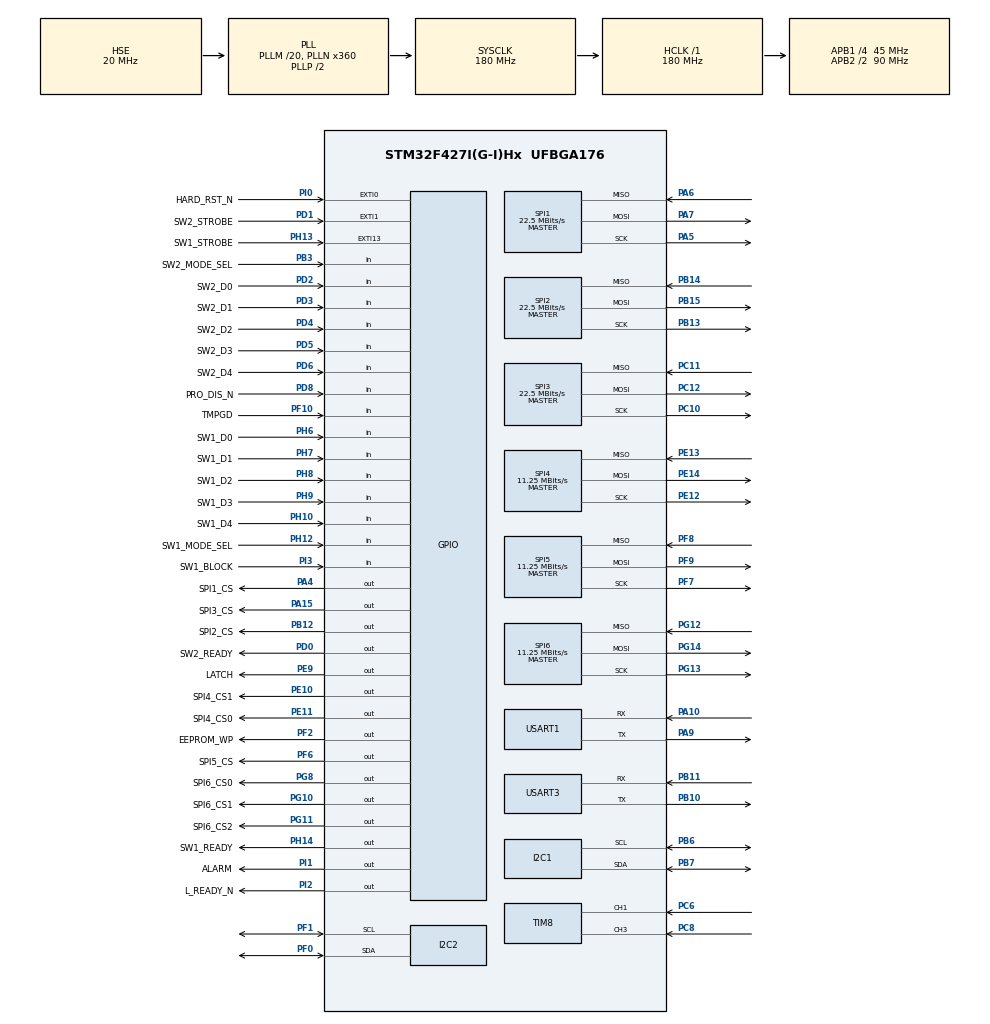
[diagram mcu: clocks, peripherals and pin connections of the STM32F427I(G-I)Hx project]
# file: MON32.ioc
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Dma.Request0=USART1_RX
Dma.USART1_RX.0.Direction=DMA_PERIPH_TO_MEMORY
Dma.USART1_RX.0.FIFOMode=DMA_FIFOMODE_DISABLE
Dma.USART1_RX.0.Instance=DMA2_Stream2
Dma.USART1_RX.0.MemDataAlignment=DMA_MDATAALIGN_BYTE
Dma.USART1_RX.0.MemInc=DMA_MINC_ENABLE
Dma.USART1_RX.0.Mode=DMA_NORMAL
Dma.USART1_RX.0.PeriphDataAlignment=DMA_PDATAALIGN_BYTE
Dma.USART1_RX.0.PeriphInc=DMA_PINC_DISABLE
Dma.USART1_RX.0.Priority=DMA_PRIORITY_VERY_HIGH
FREERTOS.Tasks01=defaultTask,24,128,StartDefaultTask,Default,NULL,Dynamic,NULL,NULL
FREERTOS.configLIBRARY_MAX_SYSCALL_INTERRUPT_PRIORITY=5
IWDG.Prescaler=IWDG_PRESCALER_32
IWDG.Reload=1500
Mcu.Family=STM32F4
Mcu.Name=STM32F427I(G-I)Hx
Mcu.Package=UFBGA176
NVIC.DMA2_Stream2_IRQn=true\:6\:0\:true\:false\:true\:true\:false\:true
NVIC.EXTI0_IRQn=true\:6\:0\:true\:false\:true\:true\:true\:true
NVIC.EXTI15_10_IRQn=true\:6\:0\:true\:false\:true\:true\:true\:true
NVIC.EXTI1_IRQn=true\:6\:0\:true\:false\:true\:true\:true\:true
NVIC.FLASH_IRQn=true\:6\:0\:true\:false\:true\:true\:true\:true
NVIC.PriorityGroup=NVIC_PRIORITYGROUP_4
NVIC.TIM1_TRG_COM_TIM11_IRQn=true\:0\:0\:false\:false\:true\:false\:false\:true
NVIC.TIM6_DAC_IRQn=true\:5\:0\:false\:false\:true\:true\:true\:true
NVIC.TIM8_CC_IRQn=true\:5\:0\:false\:false\:true\:true\:true\:true
NVIC.TimeBase=TIM1_TRG_COM_TIM11_IRQn
NVIC.TimeBaseIP=TIM11
NVIC.USART1_IRQn=true\:6\:0\:true\:false\:true\:true\:true\:true
PA10.Mode=Asynchronous
PA10.Signal=USART1_RX
PA15.GPIO_Label=SPI3_CS
PA15.Signal=GPIO_Output
PA4.GPIO_Label=SPI1_CS
PA4.Signal=GPIO_Output
PA5.Mode=Full_Duplex_Master
PA5.Signal=SPI1_SCK
PA6.Mode=Full_Duplex_Master
PA6.Signal=SPI1_MISO
PA7.Mode=Full_Duplex_Master
PA7.Signal=SPI1_MOSI
PA9.Mode=Asynchronous
PA9.Signal=USART1_TX
PB10.Mode=Asynchronous
PB10.Signal=USART3_TX
PB11.Mode=Asynchronous
PB11.Signal=USART3_RX
PB12.GPIO_Label=SPI2_CS
PB12.Signal=GPIO_Output
PB13.Mode=Full_Duplex_Master
PB13.Signal=SPI2_SCK
PB14.Mode=Full_Duplex_Master
PB14.Signal=SPI2_MISO
PB15.Mode=Full_Duplex_Master
PB15.Signal=SPI2_MOSI
PB3.GPIO_Label=SW2_MODE_SEL
PB3.Signal=GPIO_Input
PB6.Mode=I2C
PB6.Signal=I2C1_SCL
PB7.Mode=I2C
PB7.Signal=I2C1_SDA
PC10.Mode=Full_Duplex_Master
PC10.Signal=SPI3_SCK
PC11.Mode=Full_Duplex_Master
PC11.Signal=SPI3_MISO
PC12.Mode=Full_Duplex_Master
PC12.Signal=SPI3_MOSI
PC14/OSC32_IN.Mode=LSE-External-Oscillator
PC14/OSC32_IN.Signal=RCC_OSC32_IN
PC15/OSC32_OUT.Mode=LSE-External-Oscillator
PC15/OSC32_OUT.Signal=RCC_OSC32_OUT
PC6.Signal=S_TIM8_CH1
PC8.Signal=S_TIM8_CH3
PD0.GPIO_Label=SW2_READY
PD0.GPIO_PuPd=GPIO_PULLUP
PD0.Signal=GPIO_Output
PD1.GPIO_Label=SW2_STROBE
PD1.GPIO_ModeDefaultEXTI=GPIO_MODE_IT_FALLING
PD1.Signal=GPXTI1
PD13.Signal=S_TIM4_CH2
PD14.Signal=S_TIM4_CH3
PD2.GPIO_Label=SW2_D0
PD2.Signal=GPIO_Input
PD3.GPIO_Label=SW2_D1
PD3.Signal=GPIO_Input
PD4.GPIO_Label=SW2_D2
PD4.Signal=GPIO_Input
PD5.GPIO_Label=SW2_D3
PD5.Signal=GPIO_Input
PD6.GPIO_Label=SW2_D4
PD6.Signal=GPIO_Input
PD8.GPIO_Label=PRO_DIS_N
PD8.Signal=GPIO_Input
PE10.GPIO_Label=SPI4_CS1
PE10.Signal=GPIO_Output
PE11.GPIO_Label=SPI4_CS0
PE11.Signal=GPIO_Output
PE12.Mode=Full_Duplex_Master
PE12.Signal=SPI4_SCK
PE13.Mode=Full_Duplex_Master
PE13.Signal=SPI4_MISO
PE14.Mode=Full_Duplex_Master
PE14.Signal=SPI4_MOSI
PE9.GPIO_Label=LATCH
PE9.Signal=GPIO_Output
PF0.Mode=I2C
PF0.Signal=I2C2_SDA
PF1.Mode=I2C
PF1.Signal=I2C2_SCL
PF10.GPIO_Label=TMPGD
PF10.Signal=GPIO_Input
PF2.GPIO_Label=EEPROM_WP
PF2.GPIO_PuPd=GPIO_PULLUP
PF2.Signal=GPIO_Output
PF6.GPIO_Label=SPI5_CS
PF6.Signal=GPIO_Output
PF7.Mode=Full_Duplex_Master
PF7.Signal=SPI5_SCK
PF8.Mode=Full_Duplex_Master
PF8.Signal=SPI5_MISO
PF9.Mode=Full_Duplex_Master
PF9.Signal=SPI5_MOSI
PG10.GPIO_Label=SPI6_CS1
PG10.Signal=GPIO_Output
PG11.GPIO_Label=SPI6_CS2
PG11.Signal=GPIO_Output
PG12.Mode=Full_Duplex_Master
PG12.Signal=SPI6_MISO
PG13.Mode=Full_Duplex_Master
PG13.Signal=SPI6_SCK
PG14.Mode=Full_Duplex_Master
PG14.Signal=SPI6_MOSI
PG8.GPIO_Label=SPI6_CS0
PG8.Signal=GPIO_Output
PH0/OSC_IN.Mode=HSE-External-Oscillator
PH0/OSC_IN.Signal=RCC_OSC_IN
PH1/OSC_OUT.Mode=HSE-External-Oscillator
PH1/OSC_OUT.Signal=RCC_OSC_OUT
PH10.GPIO_Label=SW1_D4
PH10.Signal=GPIO_Input
PH12.GPIO_Label=SW1_MODE_SEL
PH12.Signal=GPIO_Input
PH13.GPIO_Label=SW1_STROBE
PH13.GPIO_ModeDefaultEXTI=GPIO_MODE_IT_FALLING
PH13.Signal=GPXTI13
PH14.GPIO_Label=SW1_READY
PH14.GPIO_PuPd=GPIO_PULLUP
PH14.Signal=GPIO_Output
PH6.GPIO_Label=SW1_D0
PH6.Signal=GPIO_Input
PH7.GPIO_Label=SW1_D1
PH7.Signal=GPIO_Input
PH8.GPIO_Label=SW1_D2
PH8.Signal=GPIO_Input
PH9.GPIO_Label=SW1_D3
PH9.Signal=GPIO_Input
PI0.GPIO_Label=HARD_RST_N
PI0.GPIO_ModeDefaultEXTI=GPIO_MODE_IT_FALLING
PI0.Signal=GPXTI0
PI1.GPIO_Label=ALARM
PI1.GPIO_PuPd=GPIO_PULLUP
PI1.Signal=GPIO_Output
PI2.GPIO_Label=L_READY_N
PI2.GPIO_PuPd=GPIO_PULLUP
PI2.Signal=GPIO_Output
PI3.GPIO_Label=SW1_BLOCK
PI3.Signal=GPIO_Input
ProjectManager.HeapSize=0x200
ProjectManager.StackSize=0x400
ProjectManager.TargetToolchain=MDK-ARM V5
RCC.48MHZClocksFreq_Value=90000000
RCC.AHBFreq_Value=180000000
RCC.APB1CLKDivider=RCC_HCLK_DIV4
RCC.APB1Freq_Value=45000000
RCC.APB1TimFreq_Value=90000000
RCC.APB2CLKDivider=RCC_HCLK_DIV2
RCC.APB2Freq_Value=90000000
RCC.APB2TimFreq_Value=180000000
RCC.CortexFreq_Value=180000000
RCC.HCLKFreq_Value=180000000
RCC.HSE_VALUE=20000000
RCC.HSI_VALUE=16000000
RCC.PLLM=20
RCC.PLLN=360
RCC.PLLSourceVirtual=RCC_PLLSOURCE_HSE
RCC.RCC_RTC_Clock_Source=RCC_RTCCLKSOURCE_LSE
RCC.RCC_RTC_Clock_SourceVirtual=RCC_RTCCLKSOURCE_LSE
RCC.SYSCLKFreq_VALUE=180000000
RCC.SYSCLKSource=RCC_SYSCLKSOURCE_PLLCLK
RCC.VCOOutputFreq_Value=360000000
SH.S_TIM4_CH2.0=TIM4_CH2
SH.S_TIM4_CH3.0=TIM4_CH3
SH.S_TIM8_CH1.0=TIM8_CH1,Input_Capture1_from_TI1
SH.S_TIM8_CH3.0=TIM8_CH3,Input_Capture3_from_TI3
SPI1.BaudRatePrescaler=SPI_BAUDRATEPRESCALER_4
SPI1.CLKPolarity=SPI_POLARITY_HIGH
SPI1.CalculateBaudRate=22.5 MBits/s
SPI1.Direction=SPI_DIRECTION_2LINES
SPI1.Mode=SPI_MODE_MASTER
SPI1.VirtualType=VM_MASTER
SPI2.CLKPhase=SPI_PHASE_1EDGE
SPI2.CLKPolarity=SPI_POLARITY_HIGH
SPI2.CalculateBaudRate=22.5 MBits/s
SPI2.Direction=SPI_DIRECTION_2LINES
SPI2.Mode=SPI_MODE_MASTER
SPI2.VirtualType=VM_MASTER
SPI3.BaudRatePrescaler=SPI_BAUDRATEPRESCALER_2
SPI3.CLKPhase=SPI_PHASE_2EDGE
SPI3.CalculateBaudRate=22.5 MBits/s
SPI3.Direction=SPI_DIRECTION_2LINES
SPI3.Mode=SPI_MODE_MASTER
SPI3.VirtualType=VM_MASTER
SPI4.BaudRatePrescaler=SPI_BAUDRATEPRESCALER_8
SPI4.CalculateBaudRate=11.25 MBits/s
SPI4.Direction=SPI_DIRECTION_2LINES
SPI4.Mode=SPI_MODE_MASTER
SPI4.VirtualType=VM_MASTER
SPI5.BaudRatePrescaler=SPI_BAUDRATEPRESCALER_8
SPI5.CalculateBaudRate=11.25 MBits/s
SPI5.Direction=SPI_DIRECTION_2LINES
SPI5.Mode=SPI_MODE_MASTER
SPI5.VirtualType=VM_MASTER
SPI6.BaudRatePrescaler=SPI_BAUDRATEPRESCALER_8
SPI6.CalculateBaudRate=11.25 MBits/s
SPI6.Direction=SPI_DIRECTION_2LINES
SPI6.Mode=SPI_MODE_MASTER
SPI6.VirtualType=VM_MASTER
TIM6.Period=99
TIM6.Prescaler=89
TIM8.Channel-Input_Capture1_from_TI1=TIM_CHANNEL_1
TIM8.Channel-Input_Capture3_from_TI3=TIM_CHANNEL_3
TIM8.ICFilter_CH1=0x03
TIM8.ICFilter_CH3=0x03
TIM8.ICPolarity_CH3=TIM_INPUTCHANNELPOLARITY_FALLING
USART1.VirtualMode=VM_ASYNC
USART3.VirtualMode=VM_ASYNC
VP_FREERTOS_VS_CMSIS_V2.Mode=CMSIS_V2
VP_IWDG_VS_IWDG.Mode=IWDG_Activate
VP_RTC_VS_RTC_Activate.Mode=RTC_Enabled
VP_SYS_VS_tim11.Mode=TIM11
VP_TIM6_VS_ClockSourceINT.Mode=Enable_Timer
board=custom

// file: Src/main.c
/* USER CODE BEGIN Header */
/**
  ******************************************************************************
  * @file           : main.c
  * @brief          : Main program body
  ******************************************************************************
  * @attention
  *
  * <h2><center>&copy; Copyright (c) 2020 STMicroelectronics.
  * All rights reserved.</center></h2>
  *
  * This software component is licensed by ST under Ultimate Liberty license
  * SLA0044, the "License"; You may not use this file except in compliance with
  * the License. You may obtain a copy of the License at:
  *                             www.st.com/SLA0044
  *
  ******************************************************************************
  */
/* USER CODE END Header */

#include "main.h"
#include "cmsis_os.h"
#include "dma.h"
#include "i2c.h"
#include "iwdg.h"
#include "rtc.h"
#include "spi.h"
#include "tim.h"
#include "usart.h"
#include "gpio.h"

/* USER CODE BEGIN PV */
uint8_t reset_flag = 0;
uint8_t flash_in_use;
UpgradeFlashState upgrade_status;

AlarmHistoryState history_alarm_status;

TosaCalData tosa_table[TOSA_TABLE_COUNT];
uint8_t tosa_table_count = 0;
double tosa_power_high_max_thr = 0;
double tosa_power_low_min_thr = 0;

uint8_t device_busy = 1;
uint8_t allow_tosa = 1; // Indicates allow tosa enable or not. Set by reset.
uint8_t enable_tosa_failed = 0; // Indicates endable tosa failed. Clear when pro_dis_n is 0.

const uint32_t error_file_flash_addr[] =  {  0x08100000, 0x08104000, 0x08108000, 0x0810C000, 0x08110000, 0x08120000,\
                                       0x08140000  };
const uint32_t error_file_flash_end = 0x0815FFFF;
const uint8_t error_file_flash_count = sizeof(error_file_flash_addr) / sizeof (error_file_flash_addr[0]);

const uint32_t normal_file_flash_addr[] =  {  0x08160000, 0x08180000, 0x081A0000};
const uint32_t normal_file_flash_end = 0x081BFFFF;
const uint8_t normal_file_flash_count = sizeof(normal_file_flash_addr) / sizeof (normal_file_flash_addr[0]);

LogFileState log_file_state;

//double power_arr_for_test[10];

RunTimeStatus run_status __attribute__((at(0x2002FC00)));

uint8_t lock_debug = 0;

SwTimControl sw_tim_control;
MsgStruct tim_isr_msg;
MsgStruct pro_isr_msg;
/* USER CODE END PV */

void SystemClock_Config(void);
void MX_FREERTOS_Init(void);

/* USER CODE BEGIN 0 */
extern UpgradeStruct up_state;

/* USER CODE END 0 */

int main(void)
{

  /* MCU Configuration--------------------------------------------------------*/

  /* Reset of all peripherals, Initializes the Flash interface and the Systick. */
  HAL_Init();

  /* Configure the system clock */
  SystemClock_Config();

  /* Initialize all configured peripherals */
  MX_GPIO_Init();
  MX_DMA_Init();
  MX_IWDG_Init();
  MX_RTC_Init();
  MX_I2C1_Init();
  MX_I2C2_Init();
  MX_SPI1_Init();
  MX_SPI2_Init();
  MX_SPI3_Init();
  MX_SPI4_Init();
  MX_SPI5_Init();
  MX_SPI6_Init();
  MX_TIM8_Init();
  MX_USART1_UART_Init();
  MX_USART3_UART_Init();
  MX_TIM6_Init();
  /* USER CODE BEGIN 2 */
  uint8_t buf[3] = {0};
  HAL_GPIO_WritePin(SPI1_CS_GPIO_Port, SPI1_CS_Pin, GPIO_PIN_SET);
  HAL_GPIO_WritePin(SPI2_CS_GPIO_Port, SPI2_CS_Pin, GPIO_PIN_SET);
  HAL_GPIO_WritePin(SPI3_CS_GPIO_Port, SPI3_CS_Pin, GPIO_PIN_RESET);
  if (HAL_SPI_Transmit(&hspi3, buf, 1, 10) != HAL_OK) {
    EPT("spi3 transmit filed when init\n");
  }
  HAL_GPIO_WritePin(SPI4_CS0_GPIO_Port, SPI4_CS0_Pin, GPIO_PIN_SET);
  HAL_GPIO_WritePin(SPI5_CS_GPIO_Port, SPI5_CS_Pin, GPIO_PIN_SET);
  HAL_GPIO_WritePin(SPI6_CS0_GPIO_Port, SPI6_CS0_Pin, GPIO_PIN_SET);

  run_status.internal_exp = 0;
  Set_Flag(&run_status.internal_exp, INT_EXP_CONST);
  /* USER CODE END 2 */
  /* Init scheduler */
  osKernelInitialize();

  /* Call init function for freertos objects (in freertos.c) */
  MX_FREERTOS_Init();

  /* Start scheduler */
  osKernelStart();

  /* We should never get here as control is now taken by the scheduler */

  /* Infinite loop */
  while (1)
  {

  }
}

void SystemClock_Config(void)
{
  RCC_OscInitTypeDef RCC_OscInitStruct = {0};
  RCC_ClkInitTypeDef RCC_ClkInitStruct = {0};
  RCC_PeriphCLKInitTypeDef PeriphClkInitStruct = {0};

  /** Configure the main internal regulator output voltage
  */
  __HAL_RCC_PWR_CLK_ENABLE();
  __HAL_PWR_VOLTAGESCALING_CONFIG(PWR_REGULATOR_VOLTAGE_SCALE1);
  /** Initializes the CPU, AHB and APB busses clocks
  */
  RCC_OscInitStruct.OscillatorType = RCC_OSCILLATORTYPE_LSI|RCC_OSCILLATORTYPE_HSE
                              |RCC_OSCILLATORTYPE_LSE;
  RCC_OscInitStruct.HSEState = RCC_HSE_ON;
  RCC_OscInitStruct.LSEState = RCC_LSE_ON;
  RCC_OscInitStruct.LSIState = RCC_LSI_ON;
  RCC_OscInitStruct.PLL.PLLState = RCC_PLL_ON;
  RCC_OscInitStruct.PLL.PLLSource = RCC_PLLSOURCE_HSE;
  RCC_OscInitStruct.PLL.PLLM = 20;
  RCC_OscInitStruct.PLL.PLLN = 360;
  RCC_OscInitStruct.PLL.PLLP = RCC_PLLP_DIV2;
  RCC_OscInitStruct.PLL.PLLQ = 4;
  if (HAL_RCC_OscConfig(&RCC_OscInitStruct) != HAL_OK)
  {
    Error_Handler();
  }
  /** Activate the Over-Drive mode
  */
  if (HAL_PWREx_EnableOverDrive() != HAL_OK)
  {
    Error_Handler();
  }
  /** Initializes the CPU, AHB and APB busses clocks
  */
  RCC_ClkInitStruct.ClockType = RCC_CLOCKTYPE_HCLK|RCC_CLOCKTYPE_SYSCLK
                              |RCC_CLOCKTYPE_PCLK1|RCC_CLOCKTYPE_PCLK2;
  RCC_ClkInitStruct.SYSCLKSource = RCC_SYSCLKSOURCE_PLLCLK;
  RCC_ClkInitStruct.AHBCLKDivider = RCC_SYSCLK_DIV1;
  RCC_ClkInitStruct.APB1CLKDivider = RCC_HCLK_DIV4;
  RCC_ClkInitStruct.APB2CLKDivider = RCC_HCLK_DIV2;

  if (HAL_RCC_ClockConfig(&RCC_ClkInitStruct, FLASH_LATENCY_5) != HAL_OK)
  {
    Error_Handler();
  }
  PeriphClkInitStruct.PeriphClockSelection = RCC_PERIPHCLK_RTC;
  PeriphClkInitStruct.RTCClockSelection = RCC_RTCCLKSOURCE_LSE;
  if (HAL_RCCEx_PeriphCLKConfig(&PeriphClkInitStruct) != HAL_OK)
  {
    Error_Handler();
  }
}

/* USER CODE BEGIN 4 */
void MON32_Init(void)
{
  osStatus_t status;
  uint32_t i;

  EPT("Firmware version: %s\n", fw_version);

  status = RTOS_EEPROM_Read(EEPROM_ADDR, EE_TAG_PN, (uint8_t*)pn, 16);
  pn[16] = 0;
  status |= RTOS_EEPROM_Read(EEPROM_ADDR, EE_TAG_HW_VERSION, (uint8_t*)hw_version, 4);
  hw_version[4] = 0;
  if (status != osOK) {
    Set_Flag(&run_status.internal_exp, INT_EXP_INIT);
  }

  if (__HAL_RCC_GET_FLAG(RCC_FLAG_BORRST) != RESET){
    SET_RESETFLAG(BOR_RESET_BIT);
    //EPT("BOR Reset is set\n");
  }
  if (__HAL_RCC_GET_FLAG(RCC_FLAG_PINRST) != RESET){
    SET_RESETFLAG(PIN_RESET_BIT);
    //EPT("PIN Reset is set\n");
  }
  if (__HAL_RCC_GET_FLAG(RCC_FLAG_PORRST) != RESET){
    SET_RESETFLAG(POR_RESET_BIT);
    //EPT("POR/PDR Reset is set\n");
  }
  if (__HAL_RCC_GET_FLAG(RCC_FLAG_SFTRST) != RESET){
    SET_RESETFLAG(SFT_RESET_BIT);
    //EPT("Software Reset is set\n");
  }
  if (__HAL_RCC_GET_FLAG(RCC_FLAG_IWDGRST) != RESET){
    SET_RESETFLAG(IWDG_RESET_BIT);
    //EPT("Independent Watchdog Reset is set\n");
  }
  if (__HAL_RCC_GET_FLAG(RCC_FLAG_WWDGRST) != RESET){
    SET_RESETFLAG(WWDG_RESET_BIT);
    //EPT("Window Watchdog Reset is set\n");
  }
  if (__HAL_RCC_GET_FLAG(RCC_FLAG_LPWRRST) != RESET){
    SET_RESETFLAG(LPWR_RESET_BIT);
    //EPT("Low-Power Reset is set\n");
  }
  __HAL_RCC_CLEAR_RESET_FLAGS();
  EPT("Run status maigc = %#X, uart_reset = %u\n", run_status.maigc, run_status.uart_reset);

  status = RTOS_DAC128S085_Write(0, 0, DAC128S085_MODE_WTM);
  if (status != osOK) {
    EPT("Changing DAC128S085 to WTM mode failed\n");
    Set_Flag(&run_status.internal_exp, INT_EXP_OS_ERR);
  }

  update_tosa_table();
  HAL_GPIO_WritePin(SW1_READY_GPIO_Port, SW1_READY_Pin, GPIO_PIN_SET);
  HAL_GPIO_WritePin(SW2_READY_GPIO_Port, SW2_READY_Pin, GPIO_PIN_SET);

  if (IS_RESETFLAG_SET(SFT_RESET_BIT) || IS_RESETFLAG_SET(IWDG_RESET_BIT)) {
    if (run_status.maigc == RUN_MAGIC) {
      if (run_status.uart_reset) {
        run_status.uart_reset = 0;
        EPT("Startup with UART Reset\n");
        THROW_LOG(MSG_TYPE_NORMAL_LOG, "Startup with SOFT Reset\n");
      } else {
        if (IS_RESETFLAG_SET(IWDG_RESET_BIT)) {
          EPT("Startup with WATCHDOG Reset\n");
          THROW_LOG(MSG_TYPE_NORMAL_LOG, "Startup with WATCHDOG Reset\n");
        } else {
          EPT("Startup with HARD Reset\n");
          THROW_LOG(MSG_TYPE_NORMAL_LOG, "Startup with HARD Reset\n");
        }
      }

      // exp signal
      if (run_status.exp) {
        HAL_GPIO_WritePin(ALARM_GPIO_Port, ALARM_Pin, GPIO_PIN_RESET);
      } else {
        HAL_GPIO_WritePin(ALARM_GPIO_Port, ALARM_Pin, GPIO_PIN_SET);
      }
#if 0
      // 2x32 switch signal
      if (run_status.tx_block == 1) {
        HAL_GPIO_WritePin(SW1_READY_GPIO_Port, SW1_READY_Pin, GPIO_PIN_SET);
      } else {
        if (run_status.tx_switch_channel < 0x20) {
          if (run_status.tx_switch_channel == Get_Current_Switch_Channel(TX_SWITCH_CHANNEL)) {
            HAL_GPIO_WritePin(SW1_READY_GPIO_Port, SW1_READY_Pin, GPIO_PIN_RESET);
          } else {
            EPT("Detect 2x32 optical switch channel incorrect while initializing\n");
            THROW_LOG(MSG_TYPE_ERROR_LOG, "Detect 2x32 optical switch channel %u incorrect while initializing\n", run_status.tx_switch_channel);
            Reset_Switch_Only(TX_SWITCH_CHANNEL);
            HAL_GPIO_WritePin(SW1_READY_GPIO_Port, SW1_READY_Pin, GPIO_PIN_SET);
          }
        } else {
          HAL_GPIO_WritePin(SW1_READY_GPIO_Port, SW1_READY_Pin, GPIO_PIN_SET);
        }
      }

      // 1x32 switch signal
      if (run_status.rx_switch_channel < 0x20) {
        if (run_status.rx_switch_channel == Get_Current_Switch_Channel(RX_SWITCH_CHANNEL)) {
          HAL_GPIO_WritePin(SW2_READY_GPIO_Port, SW2_READY_Pin, GPIO_PIN_RESET);
        } else {
          EPT("Detect 1x32 optical switch channel incorrect while initializing\n");
          THROW_LOG(MSG_TYPE_ERROR_LOG, "Detect 1x32 optical switch channel %u incorrect while initializing\n", run_status.rx_switch_channel);
          Reset_Switch_Only(RX_SWITCH_CHANNEL);
          HAL_GPIO_WritePin(SW2_READY_GPIO_Port, SW2_READY_Pin, GPIO_PIN_SET);
        }
      } else {
        HAL_GPIO_WritePin(SW2_READY_GPIO_Port, SW2_READY_Pin, GPIO_PIN_SET);
      }
#endif
      // Modulation
      if (run_status.modulation) {
        HAL_TIM_IC_Start_IT(&htim8, TIM_CHANNEL_1);
        HAL_TIM_IC_Start_IT(&htim8, TIM_CHANNEL_3);
      }

      // Lazer
      if (run_status.lazer_ready) {
        HAL_GPIO_WritePin(L_READY_N_GPIO_Port, L_READY_N_Pin, GPIO_PIN_RESET);
      } else {
        HAL_GPIO_WritePin(L_READY_N_GPIO_Port, L_READY_N_Pin, GPIO_PIN_SET);
      }

      HAL_GPIO_WritePin(LATCH_GPIO_Port, LATCH_Pin, GPIO_PIN_SET);
      osDelay(pdMS_TO_TICKS(1));
      HAL_GPIO_WritePin(LATCH_GPIO_Port, LATCH_Pin, GPIO_PIN_RESET);
    } else {
      // Init device
      Reset_Switch_Only(TX_SWITCH_CHANNEL);
      MON32_Init_Dev();
      EPT("Variable run_status exception\n");
      THROW_LOG(MSG_TYPE_ERROR_LOG, "Variable run_status exception\n");
    }
  } else if (IS_RESETFLAG_SET(BOR_RESET_BIT) || IS_RESETFLAG_SET(POR_RESET_BIT)) {
    // Init device
    MON32_Init_Dev();
    EPT("Startup with POWER Reset\n");
    //THROW_LOG("Startup with POWER Reset\n");
  } else {
    // Init device
    run_status.maigc = 0;
    Reset_Switch_Only(TX_SWITCH_CHANNEL);
    //Disable_Tosa();
    MON32_Init_Dev();
    EPT("Startup with MASTER Reset\n");
    THROW_LOG(MSG_TYPE_NORMAL_LOG, "Startup with MASTER Reset\n");
  }

  up_state.run = RUN_MODE_APPLICATION;
  up_state.is_erasing = 0;
  flash_in_use = 0;

  FLASH_If_Init();
  status = Get_Up_Status(&upgrade_status);
  if (status) {
    EPT("Get upgrade status failed, status = %d\n", status);
    THROW_LOG(MSG_TYPE_ERROR_LOG, "Get upgrade status failed, status = %d\n", status);
  }
  EPT("upgrade_status: %#X, %u, %u, %u, %#X, %u, %#X\n", upgrade_status.magic, upgrade_status.run, upgrade_status.flash_empty, upgrade_status.length, upgrade_status.crc32,\
                upgrade_status.factory_length, upgrade_status.factory_crc32);

  if (upgrade_status.magic != UPGRADE_MAGIC) {
    EPT("Verify upgrade magic failed\n");
    THROW_LOG(MSG_TYPE_ERROR_LOG, "Verify upgrade magic failed\n");
  }
  switch (upgrade_status.run) {
    case 0:
      EPT("Boot from factory\n");
      up_state.upgrade_addr = APPLICATION_1_ADDRESS;
      up_state.upgrade_sector = APPLICATION_1_SECTOR;
      break;
    case 1:
      EPT("Boot from Application 1\n");
      up_state.upgrade_addr = APPLICATION_2_ADDRESS;
      up_state.upgrade_sector = APPLICATION_2_SECTOR;
      break;
    case 2:
      EPT("Boot from Application 2\n");
      up_state.upgrade_addr = APPLICATION_1_ADDRESS;
      up_state.upgrade_sector = APPLICATION_1_SECTOR;
      break;
    default:
      EPT("f_state.run invalid\n");
      THROW_LOG(MSG_TYPE_ERROR_LOG, "f_state.run invalid\n");
      up_state.upgrade_addr = RESERVE_ADDRESS;
      up_state.upgrade_sector = RESERVE_SECTOR;
      break;
  }
  EPT("FLASH->OPTCR = %#X\n", FLASH->OPTCR);
  if (!upgrade_status.flash_empty) {
    flash_in_use = 1;
    up_state.is_erasing = 1;
    // erase flash
    EPT("flash is not empty\n");
    if (up_state.upgrade_addr != RESERVE_ADDRESS)
      FLASH_If_Erase_IT(up_state.upgrade_sector);
    EPT("erase sector...\n");
  } else {
    EPT("flash is empty\n");
  }

  // log
  Get_Log_Status(&log_file_state);
  EPT("log_file_state: %#X, %#X\n", log_file_state.offset, log_file_state.header);
  for (i = 0; i < error_file_flash_count - 1; ++i) {
    if (log_file_state.error_offset < error_file_flash_addr[i + 1]) {
      break;
    }
  }
  log_file_state.error_cur_sector = ERROR_LOG_FIRST_SECTOR + i;

  for (i = 0; i < normal_file_flash_count - 1; ++i) {
    if (log_file_state.normal_offset < normal_file_flash_addr[i + 1]) {
      break;
    }
  }
  log_file_state.normal_cur_sector = NORMAL_LOG_FIRST_SECTOR + i;

  // alarm
  if ((status = Get_EEPROM_Alarm_Status(&history_alarm_status)) != osOK) {
    Set_Flag(&run_status.internal_exp, INT_EXP_OS_ERR);
  }

  // check calibration data
  Check_Cali();
}

void MON32_Init_Dev(void)
{
  osStatus_t status;

  HAL_GPIO_WritePin(ALARM_GPIO_Port, ALARM_Pin, GPIO_PIN_SET);
  HAL_GPIO_WritePin(L_READY_N_GPIO_Port, L_READY_N_Pin, GPIO_PIN_SET);
  HAL_GPIO_WritePin(LATCH_GPIO_Port, LATCH_Pin, GPIO_PIN_SET);
  osDelay(pdMS_TO_TICKS(1));
  HAL_GPIO_WritePin(LATCH_GPIO_Port, LATCH_Pin, GPIO_PIN_RESET);
  Init_Run_Status();
  Get_Threshold_Table(&run_status.thr_table);
  Reset_Tec_Dest_Temp(&run_status.thr_table);

  run_status.tosa_high = Get_Tosa_Data(run_status.tosa_dst_power_high);
  run_status.tosa_low = Get_Tosa_Data(run_status.tosa_dst_power_low);
  status = RTOS_DAC128S085_Write(DAC128S085_TOSA_SWITCH_CHANNEL, 0, DAC128S085_MODE_NORMAL);
  status |= RTOS_DAC128S085_Write(DAC128S085_TEC_SWITCH_CHANNEL, 0, DAC128S085_MODE_NORMAL);
  status |= RTOS_DAC128S085_Write(DAC128S085_TEC_VALUE_CHANNEL, 0, DAC128S085_MODE_NORMAL);
  status |= RTOS_DAC128S085_Write(DAC128S085_TOSA_POWER_CHANNEL, 0, DAC128S085_MODE_NORMAL);
  if (status != osOK) {
    Set_Flag(&run_status.internal_exp, INT_EXP_OS_ERR);
  }
}

extern FLASH_ProcessTypeDef pFlash;
extern osMessageQueueId_t mid_ISR;
extern osMessageQueueId_t mid_SwISR;
extern osMessageQueueId_t mid_LazerManager;
extern osSemaphoreId_t logEraseSemaphore;
void HAL_FLASH_EndOfOperationCallback(uint32_t ReturnValue)
{
  MsgStruct isr_msg;
  if (0xFFFFFFFFU == ReturnValue) {
    EPT("Erase flash operation completely\n");
    HAL_FLASH_Lock();
    flash_in_use = 0;
    if (up_state.is_erasing == 0) {
      // send signal to logTask
      osSemaphoreRelease(logEraseSemaphore);
    } else {
      upgrade_status.flash_empty = 1;
      up_state.is_erasing = 0;
      isr_msg.type = MSG_TYPE_FLASH_ISR;
      osMessageQueuePut(mid_ISR, &isr_msg, 0U, 0U);
    }
  }
}

void HAL_TIM_IC_CaptureCallback(TIM_HandleTypeDef *htim)
{
  if (htim->Instance == TIM8) {
    if (htim->Channel == HAL_TIM_ACTIVE_CHANNEL_1) {
      // Rising Edge
      pro_isr_msg.type = MSG_TYPE_PRO_CTL_RAISING_ISR;
      osMessageQueuePut(mid_LazerManager, &pro_isr_msg, 0U, 0U);
      //RTOS_DAC128S085_Write_Nodelay(DAC128S085_TOSA_POWER_CHANNEL, run_status.tosa_high.tosa_dac, DAC128S085_MODE_NORMAL);
      //run_status.power_mode = 1;
    } else if (htim->Channel == HAL_TIM_ACTIVE_CHANNEL_3) {
      // Failing Edge
      pro_isr_msg.type = MSG_TYPE_PRO_CTL_FALLING_ISR;
      osMessageQueuePut(mid_LazerManager, &pro_isr_msg, 0U, 0U);
      //RTOS_DAC128S085_Write_Nodelay(DAC128S085_TOSA_POWER_CHANNEL, run_status.tosa_low.tosa_dac, DAC128S085_MODE_NORMAL);
      //run_status.power_mode = 0;
    }
  }
}

void HAL_GPIO_EXTI_Callback(uint16_t GPIO_Pin)
{
  MsgStruct isr_msg;

  if (GPIO_Pin == SW1_STROBE_Pin) {
    if (HAL_GPIO_ReadPin(SW1_MODE_SEL_GPIO_Port, SW1_MODE_SEL_Pin) == GPIO_PIN_SET) {
    } else {
      isr_msg.type = MSG_TYPE_SWITCH1_ISR;
      osMessageQueuePut(mid_ISR, &isr_msg, 0U, 0U);
    }
  } else if (GPIO_Pin == SW2_STROBE_Pin) {
    if (HAL_GPIO_ReadPin(SW2_MODE_SEL_GPIO_Port, SW2_MODE_SEL_Pin) == GPIO_PIN_SET) {
    } else {
      isr_msg.type = MSG_TYPE_SWITCH2_ISR;
      osMessageQueuePut(mid_ISR, &isr_msg, 0U, 0U);
    }
  } else if (GPIO_Pin == HARD_RST_N_Pin) {
    __NVIC_SystemReset();
    while (1) {
    }
  }
}

/* USER CODE END 4 */

void HAL_TIM_PeriodElapsedCallback(TIM_HandleTypeDef *htim)
{
  if (htim->Instance == TIM11) {
    HAL_IncTick();
  }
  /* USER CODE BEGIN Callback 1 */
  if (htim->Instance == TIM6) {
    if (++sw_tim_control.counter < sw_tim_control.time) {
    } else {
      HAL_TIM_Base_Stop_IT(&htim6);
      tim_isr_msg.type = MSG_TYPE_SWITCH_DAC_ISR;
      osMessageQueuePut(mid_SwISR, &tim_isr_msg, 0U, 0U);
      sw_tim_control.counter = 0;
    }
  }
  /* USER CODE END Callback 1 */
}

void Error_Handler(void)
{
}

/************************ (C) COPYRIGHT STMicroelectronics *****END OF FILE****/

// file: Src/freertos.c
/* USER CODE BEGIN Header */
/**
  ******************************************************************************
  * File Name          : freertos.c
  * Description        : Code for freertos applications
  ******************************************************************************
  * @attention
  *
  * <h2><center>&copy; Copyright (c) 2020 STMicroelectronics.
  * All rights reserved.</center></h2>
  *
  * This software component is licensed by ST under Ultimate Liberty license
  * SLA0044, the "License"; You may not use this file except in compliance with
  * the License. You may obtain a copy of the License at:
  *                             www.st.com/SLA0044
  *
  ******************************************************************************
  */
/* USER CODE END Header */

#include "FreeRTOS.h"
#include "task.h"
#include "main.h"
#include "cmsis_os.h"

/* USER CODE BEGIN Includes */
#include "command.h"
#include "iwdg.h"
#include "flash_if.h"
#include "functions.h"
#include "tim.h"

/* USER CODE END Includes */

/* USER CODE BEGIN Variables */
osSemaphoreId_t uartProcessSemaphore;
osSemaphoreId_t cmdProcessSemaphore;
osSemaphoreId_t switchSemaphore;
osSemaphoreId_t logEraseSemaphore;                  // semaphore id

osMessageQueueId_t mid_LogMsg;
osMessageQueueId_t mid_ISR;                // message queue id
osMessageQueueId_t mid_SwISR;                // message queue id
osMessageQueueId_t mid_LazerManager;                // message queue id
osMessageQueueId_t mid_CmdProcess;                // message queue id

osMutexId_t i2c1Mutex;
osMutexId_t i2c2Mutex;
osMutexId_t spi2Mutex;
osMutexId_t spi3Mutex;
osMutexId_t spi4Mutex;
osMutexId_t spi5Mutex;
osMutexId_t spi6Mutex;
osMutexId_t swMutex;
const osMutexAttr_t Thread_Mutex_attr = {
  "Mutex",                              // human readable mutex name
  osMutexPrioInherit,                       // attr_bits
  NULL,                                     // memory for control block
  0U                                        // size for control block
};

osThreadId_t cmdProcessTaskHandle;
const osThreadAttr_t cmdProcessTask_attributes = {
  .name = "cmdProcessTask",
  .priority = (osPriority_t) CMD_PROCESS_PRIORITY,
  .stack_size = 2048
};

osThreadId_t uartProcessTaskHandle;
const osThreadAttr_t uartProcessTask_attributes = {
  .name = "uartProcessTask",
  .priority = (osPriority_t) UART_PROCESS_PRIORITY,
  .stack_size = 1024
};

osThreadId_t watchdogTaskHandle;
const osThreadAttr_t watchdogTask_attributes = {
  .name = "watchdogTask",
  .priority = (osPriority_t) WATCHDOG_PRIORITY,
  .stack_size = 512
};

osThreadId_t isrTaskHandle;
const osThreadAttr_t isrTask_attributes = {
  .name = "isrTask",
  .priority = (osPriority_t) INTERRUPT_TASK_PRIORITY,
  .stack_size = 1024
};

osThreadId_t swIsrTaskHandle;
const osThreadAttr_t swIsrTask_attributes = {
  .name = "swIsrTask",
  .priority = (osPriority_t) INTERRUPT_TASK_PRIORITY,
  .stack_size = 1024
};

osThreadId_t logTaskHandle;
const osThreadAttr_t logTask_attributes = {
  .name = "logTask",
  .priority = (osPriority_t) LOG_MESSAGE_PRIORITY,
  .stack_size = 1024
};

osThreadId_t monTaskHandle;
const osThreadAttr_t monTask_attributes = {
  .name = "monTask",
  .priority = (osPriority_t) MONITOR_PRIORITY,
  .stack_size = 1024
};

osThreadId_t lazerManagerTaskHandle;
const osThreadAttr_t lazerManagerTask_attributes = {
  .name = "lazerManagerTask",
  .priority = (osPriority_t) LAZER_MANAGER_PRIORITY,
  .stack_size = 1024
};

/* USER CODE END Variables */
/* Definitions for defaultTask */
osThreadId_t defaultTaskHandle;
const osThreadAttr_t defaultTask_attributes = {
  .name = "defaultTask",
  .priority = (osPriority_t) osPriorityNormal,
  .stack_size = 128
};

/* USER CODE BEGIN FunctionPrototypes */
void uartProcessTask(void *argument);
void cmdProcessTask(void *argument);
void watchdogTask(void *argument);
void isrTask(void *argument);
void swIsrTask(void *argument);
void logTask(void *argument);
void monitorTask(void *argument);
void lazerManagerTask(void *argument);

/* USER CODE END FunctionPrototypes */

void StartDefaultTask(void *argument);

void MX_FREERTOS_Init(void); /* (MISRA C 2004 rule 8.1) */

void MX_FREERTOS_Init(void) {

  /* USER CODE BEGIN RTOS_SEMAPHORES */
  /* add semaphores, ... */
  uartProcessSemaphore = osSemaphoreNew(1U, 0U, NULL);
  if (uartProcessSemaphore == NULL) {
    Set_Flag(&run_status.internal_exp, INT_EXP_INIT);
  }

  cmdProcessSemaphore = osSemaphoreNew(1U, 0U, NULL);
  if (cmdProcessSemaphore == NULL) {
    Set_Flag(&run_status.internal_exp, INT_EXP_INIT);
  }

  switchSemaphore = osSemaphoreNew(1U, 0U, NULL);
  if (switchSemaphore == NULL) {
    Set_Flag(&run_status.internal_exp, INT_EXP_INIT);
  }

  logEraseSemaphore = osSemaphoreNew(1U, 0U, NULL);
  if (logEraseSemaphore == NULL) {
    Set_Flag(&run_status.internal_exp, INT_EXP_INIT);
  }

  mid_LogMsg = osMessageQueueNew(LOG_QUEUE_LENGTH, sizeof(MsgStruct), NULL);
  if (mid_LogMsg == NULL) {
    Set_Flag(&run_status.internal_exp, INT_EXP_INIT);
  }

  mid_ISR = osMessageQueueNew(ISR_QUEUE_LENGTH, sizeof(MsgStruct), NULL);
  if (mid_ISR == NULL) {
    Set_Flag(&run_status.internal_exp, INT_EXP_INIT);
  }

  mid_SwISR = osMessageQueueNew(SW_ISR_QUEUE_LENGTH, sizeof(MsgStruct), NULL);
  if (mid_SwISR == NULL) {
    Set_Flag(&run_status.internal_exp, INT_EXP_INIT);
  }

  mid_LazerManager = osMessageQueueNew(LM_QUEUE_LENGTH, sizeof(MsgStruct), NULL);
  if (mid_LazerManager == NULL) {
    Set_Flag(&run_status.internal_exp, INT_EXP_INIT);
  }

  mid_CmdProcess = osMessageQueueNew(LM_QUEUE_LENGTH, sizeof(MsgStruct), NULL);
  if (mid_CmdProcess == NULL) {
    Set_Flag(&run_status.internal_exp, INT_EXP_INIT);
  }

  i2c1Mutex = osMutexNew(&Thread_Mutex_attr);
  if (i2c1Mutex == NULL) {
    Set_Flag(&run_status.internal_exp, INT_EXP_INIT);
  }

  i2c2Mutex = osMutexNew(&Thread_Mutex_attr);
  if (i2c2Mutex == NULL) {
    Set_Flag(&run_status.internal_exp, INT_EXP_INIT);
  }

  spi2Mutex = osMutexNew(&Thread_Mutex_attr);
  if (spi2Mutex == NULL) {
    Set_Flag(&run_status.internal_exp, INT_EXP_INIT);
  }

  spi3Mutex = osMutexNew(&Thread_Mutex_attr);
  if (spi3Mutex == NULL) {
    Set_Flag(&run_status.internal_exp, INT_EXP_INIT);
  }

  spi4Mutex = osMutexNew(&Thread_Mutex_attr);
  if (spi4Mutex == NULL) {
    Set_Flag(&run_status.internal_exp, INT_EXP_INIT);
  }

  spi5Mutex = osMutexNew(&Thread_Mutex_attr);
  if (spi5Mutex == NULL) {
    Set_Flag(&run_status.internal_exp, INT_EXP_INIT);
  }

  spi6Mutex = osMutexNew(&Thread_Mutex_attr);
  if (spi6Mutex == NULL) {
    Set_Flag(&run_status.internal_exp, INT_EXP_INIT);
  }

  swMutex = osMutexNew(&Thread_Mutex_attr);
  if (swMutex == NULL) {
    Set_Flag(&run_status.internal_exp, INT_EXP_INIT);
  }

  /* USER CODE END RTOS_SEMAPHORES */

  /* Create the thread(s) */
  /* creation of defaultTask */
  defaultTaskHandle = osThreadNew(StartDefaultTask, NULL, &defaultTask_attributes);

  /* USER CODE BEGIN RTOS_THREADS */
  /* add threads, ... */
  uartProcessTaskHandle = osThreadNew(uartProcessTask, NULL, &uartProcessTask_attributes);
  cmdProcessTaskHandle = osThreadNew(cmdProcessTask, NULL, &cmdProcessTask_attributes);
  watchdogTaskHandle = osThreadNew(watchdogTask, NULL, &watchdogTask_attributes);
  isrTaskHandle = osThreadNew(isrTask, NULL, &isrTask_attributes);
  swIsrTaskHandle = osThreadNew(swIsrTask, NULL, &swIsrTask_attributes);
  logTaskHandle = osThreadNew(logTask, NULL, &logTask_attributes);
  monTaskHandle = osThreadNew(monitorTask, NULL, &monTask_attributes);
  lazerManagerTaskHandle = osThreadNew(lazerManagerTask, NULL, &lazerManagerTask_attributes);
  /* USER CODE END RTOS_THREADS */

}

void StartDefaultTask(void *argument)
{
  for(;;)
  {
    osDelay(1);
  }
}

/* USER CODE BEGIN Application */
extern TransStu trans_buf;
extern RespondStu resp_buf;
struct UartTaskSync{
  uint8_t ProcessOnGoing;
  uint8_t ProcessTimeout;
} uart_sync;

void uartProcessTask(void *argument)
{
  uint8_t msg_length;
  uint16_t msg_id;
  uint8_t chk;
  uint32_t wait_time;
  uint16_t *p16;
  osStatus_t status;

  CLEAR_BIT(huart1.Instance->SR, USART_SR_RXNE);
  __HAL_UART_FLUSH_DRREGISTER(&huart1);
  HAL_UART_Receive_IT(&huart1, trans_buf.buf, 1);

  uart_sync.ProcessTimeout = 0;
  uart_sync.ProcessOnGoing = 0;
  trans_buf.stage = TRANS_WAIT_START;

  for(;;)
  {
    if (trans_buf.stage == TRANS_WAIT_START) {
      wait_time = osWaitForever;
    } else if (trans_buf.stage == TRANS_WAIT_HEADER) {
      wait_time = pdMS_TO_TICKS(TRANS_WAIT_HEAD_TIME);
    } else if (trans_buf.stage == TRANS_RECV_DATA) {
      wait_time = pdMS_TO_TICKS(TRANS_WAIT_TIME);
    }
    status = osSemaphoreAcquire(uartProcessSemaphore, wait_time / 2);
    if (status != osOK) {
      HAL_UART_DMAStop(&huart1);
      EPT("DMA timeout, stage = %u, ErrorCode = %#X\n", trans_buf.stage, huart1.ErrorCode);
      THROW_LOG(MSG_TYPE_ERROR_LOG, "DMA timeout, stage = %u, ErrorCode = %#X\n", trans_buf.stage, huart1.ErrorCode);
      Uart_Respond(msg_id, RESPOND_FAILURE, NULL, 0);
      trans_buf.stage = TRANS_WAIT_START;
      HAL_UART_Receive_IT(&huart1, trans_buf.buf, 1);
      continue;
    }

    if (trans_buf.stage == TRANS_WAIT_START) {
      // Received start byte
      if (trans_buf.buf[0] != TRANS_START_BYTE) {
        // Invalid data
        EPT("Invalid character: %#X\n", trans_buf.buf[0]);
        HAL_UART_Receive_IT(&huart1, trans_buf.buf, 1);
      } else {
        // Prepare to receive message header
        msg_id = 0;
        trans_buf.stage = TRANS_WAIT_HEADER;
        HAL_UART_Receive_DMA(&huart1, &trans_buf.buf[1], 3);
      }
    } else if (trans_buf.stage == TRANS_WAIT_HEADER) {
      // Received message header
      p16 = (uint16_t*)&trans_buf.buf[CMD_SEQ_MSG_ID];
      msg_id = switch_endian_16(*p16);
      msg_length = trans_buf.buf[CMD_SEQ_MSG_LENGTH];
      if (msg_length < 4) {
        // Length invalid
        PRINT_HEX("buf", trans_buf.buf, 4);
        EPT("Invalid length %#X\n", msg_length);
        THROW_LOG(MSG_TYPE_ERROR_LOG, "Invalid length %#X\n", msg_length);
        Uart_Respond(msg_id, RESPOND_FAILURE, NULL, 0);
        trans_buf.stage = TRANS_WAIT_START;
        HAL_UART_Receive_IT(&huart1, trans_buf.buf, 1);
      } else {
        trans_buf.stage = TRANS_RECV_DATA;
        HAL_UART_Receive_DMA(&huart1, &trans_buf.buf[CMD_SEQ_MSG_DATA], msg_length - 3);
        //EPT("Message Length: %u, ID: %u\n", msg_length, msg_id);
        trans_buf.length = msg_length + 1;
      }
    } else if (trans_buf.stage == TRANS_RECV_DATA){
      // Received message data
      //PRINT_HEX("buf", trans_buf.buf, trans_buf.length);

      // TODO: Check CRC
      chk = Cal_Check((uint8_t*)&trans_buf.buf[1], trans_buf.length - 1 - 1);
      if (chk ^ trans_buf.buf[trans_buf.length - 1]) {
        // Incorrect
        THROW_LOG(MSG_TYPE_ERROR_LOG, "UART Checksum verification failed, msg_length = %#X, cid = %#X, chk = %#X, rcv_chk = %#X\n",\
          msg_length, msg_id, chk, trans_buf.buf[trans_buf.length - 1]);
        EPT("msg_length = %#X, trans_buf.length = %#X, chk = %#X, rcv_chk = %#X\n", msg_length, trans_buf.length, chk, trans_buf.buf[trans_buf.length - 1]);
        PRINT_HEX("buf", trans_buf.buf, trans_buf.length);
        FILL_RESP_MSG(msg_id, RESPOND_CHECK_ERR, 0);
      } else {
        if (!uart_sync.ProcessOnGoing) {
          // Process Command and Respond
          xTaskNotifyGive(cmdProcessTaskHandle);
          status = osSemaphoreAcquire(cmdProcessSemaphore, pdMS_TO_TICKS(COMMAND_PROCESS_TIME) / 2);
          if (status == osErrorTimeout) {
            // TODO: Process command timeout
            THROW_LOG(MSG_TYPE_ERROR_LOG, "Process command %#X timeout\n", msg_id);
            EPT("Process command timeout\n");
            uart_sync.ProcessTimeout = 1;
            FILL_RESP_MSG(msg_id, RESPOND_FAILURE, 0);
          } else if (status != osOK) {
            EPT("Error, status=%#X\n", status);
            THROW_LOG(MSG_TYPE_ERROR_LOG, "Process command failed, status=%#X\n", status);
            FILL_RESP_MSG(msg_id, RESPOND_FAILURE, 0);
          } else {
            // success
          }
        } else {
            EPT("Detected process is ongoing\n");
            THROW_LOG(MSG_TYPE_ERROR_LOG, "Detected process is ongoing\n");
            FILL_RESP_MSG(msg_id, RESPOND_FAILURE, 0);
        }
      }

      trans_buf.stage = TRANS_WAIT_START;
      HAL_UART_Receive_IT(&huart1, trans_buf.buf, 1);
      Uart_Respond(resp_buf.cmd, resp_buf.status, resp_buf.buf, resp_buf.length);
    }
  }
}

void cmdProcessTask(void *argument)
{
  for (;;)
  {
    ulTaskNotifyTake(pdTRUE, portMAX_DELAY);
    if (trans_buf.stage != TRANS_RECV_DATA) {
      EPT("Stage incorrect\n");
      THROW_LOG(MSG_TYPE_ERROR_LOG, "Stage incorrect\n");
      continue;
    }

    uart_sync.ProcessOnGoing = 1;
    Cmd_Process();

    if (uart_sync.ProcessTimeout == 0) {
      osSemaphoreRelease(cmdProcessSemaphore);
      //Uart_Respond(resp_buf.cmd, resp_buf.status, resp_buf.buf, resp_buf.length);
    } else {
      EPT("Detected process timeout\n");
      THROW_LOG(MSG_TYPE_ERROR_LOG, "Detected process timeout\n");
      uart_sync.ProcessTimeout = 0;
    }

    uart_sync.ProcessOnGoing = 0;
  }
}

void watchdogTask(void *argument)
{
  uint32_t delay = pdMS_TO_TICKS(WATCH_DOG_DELAY_TIME);

  HAL_IWDG_Refresh(&hiwdg);
  for(;;)
  {
    //EPT("Feed dog\n");
    osDelay(delay);
    HAL_IWDG_Refresh(&hiwdg);
  }
}

extern UpgradeFlashState upgrade_status;
void isrTask(void *argument)
{
  osStatus_t status;
  MsgStruct msg;
  uint8_t switch_channel, switch_pos;
  //uint32_t switch_channel;

  MON32_Init();

  for (;;)
  {
    status = osMessageQueueGet(mid_ISR, &msg, 0U, osWaitForever);
    if (status != osOK)
      continue;

    if (msg.type == MSG_TYPE_FLASH_ISR) {
      EPT("Received MSG_TYPE_FLASH_ISR, flash_empty = %u\n", upgrade_status.flash_empty);
      status = Update_Up_Status(&upgrade_status);
      if (status != osOK) {
        EPT("Update upgrade status to eeprom failed\n");
      }
    } else if (msg.type == MSG_TYPE_SWITCH1_ISR) {
      switch_channel = TX_SWITCH_CHANNEL;
      switch_pos = Get_Switch_Position_By_IO(switch_channel);
      EPT("Switch channel is %u, Switch position is %u\n", switch_channel, switch_pos);
      if (switch_pos >= 0x20) {
        EPT("Invalid switch position = %u [io]\n", switch_pos);
        THROW_LOG(MSG_TYPE_ERROR_LOG, "Invalid switch position = %u [io]\n", switch_pos);
        continue;
      }

      if (run_status.tx_block) {
        run_status.tx_switch_channel = switch_pos;
        continue;
      }

      if ((status = osMutexAcquire(swMutex, 50)) != osOK) {
        THROW_LOG(MSG_TYPE_ERROR_LOG, "Acquire mutex of sw failed\n");
        continue;
      }

      Clear_Switch_Ready(switch_channel);
      if (Set_Switch(switch_channel, switch_pos)) {
        run_status.tx_switch_channel = 0xFF;
        THROW_LOG(MSG_TYPE_NORMAL_LOG, "Set Switch failed in io mode\n");
        osMutexRelease(swMutex);
        continue;
      }

      run_status.tx_switch_channel = switch_pos;

      // Check
      if (Get_Current_Switch_Channel(switch_channel) != switch_pos) {
        Reset_Switch(switch_channel);
        THROW_LOG(MSG_TYPE_NORMAL_LOG, "Check Switch abnormal\n");
        osMutexRelease(swMutex);
        continue;
      }

      Set_Switch_Ready(switch_channel);
      osMutexRelease(swMutex);
    } else if (msg.type == MSG_TYPE_SWITCH2_ISR) {
      switch_channel = RX_SWITCH_CHANNEL;
      switch_pos = Get_Switch_Position_By_IO(switch_channel);
      EPT("Switch channel is %u, Switch position is %u\n", switch_channel, switch_pos);
      if (switch_pos >= 0x20) {
        EPT("Invalid switch position = %u [io]\n", switch_pos);
        THROW_LOG(MSG_TYPE_ERROR_LOG, "Invalid switch position = %u [io]\n", switch_pos);
        continue;
      }

      if ((status = osMutexAcquire(swMutex, 50)) != osOK) {
        THROW_LOG(MSG_TYPE_ERROR_LOG, "Acquire mutex of sw failed\n");
        continue;
      }

      Clear_Switch_Ready(switch_channel);
      if (Set_Switch(switch_channel, switch_pos)) {
        run_status.rx_switch_channel = 0xFF;
        THROW_LOG(MSG_TYPE_NORMAL_LOG, "Set Switch failed in io mode\n");
        osMutexRelease(swMutex);
        continue;
      }

      run_status.rx_switch_channel = switch_pos;
      // osDelay(pdMS_TO_TICKS(4));

      // Check
      if (Get_Current_Switch_Channel(switch_channel) != switch_pos) {
        Reset_Switch(switch_channel);
        THROW_LOG(MSG_TYPE_NORMAL_LOG, "Check Switch abnormal\n");
        osMutexRelease(swMutex);
        continue;
      }

      Set_Switch_Ready(switch_channel);
      osMutexRelease(swMutex);
    } else if (msg.type == MSG_TYPE_SELF_CHECK_SWITCH) {
      if (run_status.osc_status == OSC_ONGOING) {
        msg.type = MSG_TYPE_SELF_TEST_STEP_2;
        msg.pbuf = NULL;

        if ((status = osMutexAcquire(swMutex, 50)) != osOK) {
          THROW_LOG(MSG_TYPE_ERROR_LOG, "Acquire mutex of sw failed\n");
          run_status.osc_status = OSC_FAILURE;
          osMessageQueuePut(mid_LazerManager, &msg, 0U, 0U);
          continue;
        }

        // Switch Loopback
        Clear_Switch_Ready(TX_SWITCH_CHANNEL);
        if (Set_Switch(TX_SWITCH_CHANNEL, 32)) {
          run_status.tx_switch_channel = 0xFF;
          THROW_LOG(MSG_TYPE_ERROR_LOG, "Set Tx Switch failed\n");
          run_status.osc_status = OSC_FAILURE;
          osMutexRelease(swMutex);
          osMessageQueuePut(mid_LazerManager, &msg, 0U, 0U);
          continue;
        }
        run_status.tx_switch_channel = 32;
        // Check
        if (Get_Current_Switch_Channel(TX_SWITCH_CHANNEL) != 32) {
          THROW_LOG(MSG_TYPE_ERROR_LOG, "Set Tx Switch failed 2\n");
          run_status.osc_status = OSC_FAILURE;
          osMutexRelease(swMutex);
          osMessageQueuePut(mid_LazerManager, &msg, 0U, 0U);
          continue;
        }

        Clear_Switch_Ready(RX_SWITCH_CHANNEL);
        if (Set_Switch(RX_SWITCH_CHANNEL, 32)) {
          run_status.rx_switch_channel = 0xFF;
          THROW_LOG(MSG_TYPE_ERROR_LOG, "Set Rx Switch failed\n");
          run_status.osc_status = OSC_FAILURE;
          osMutexRelease(swMutex);
          osMessageQueuePut(mid_LazerManager, &msg, 0U, 0U);
          continue;
        }
        run_status.rx_switch_channel = 32;
        // Check
        if (Get_Current_Switch_Channel(RX_SWITCH_CHANNEL) != 32) {
          THROW_LOG(MSG_TYPE_ERROR_LOG, "Set Rx Switch failed 2\n");
          run_status.osc_status = OSC_FAILURE;
          osMutexRelease(swMutex);
          osMessageQueuePut(mid_LazerManager, &msg, 0U, 0U);
          continue;
        }

        osMutexRelease(swMutex);
        osMessageQueuePut(mid_LazerManager, &msg, 0U, 0U);
      } else if (run_status.osc_status == OSC_SUCCESS) {
        if ((status = osMutexAcquire(swMutex, 50)) != osOK) {
          THROW_LOG(MSG_TYPE_ERROR_LOG, "Acquire mutex of sw failed\n");
          continue;
        }

        Clear_Switch_Ready(TX_SWITCH_CHANNEL);
        if (run_status.tx_block) {
          Reset_Switch_Only(TX_SWITCH_CHANNEL);
          run_status.tx_switch_channel = 0;
        } else {
          if (Set_Switch(TX_SWITCH_CHANNEL, 0)) {
            run_status.tx_switch_channel = 0xFF;
            THROW_LOG(MSG_TYPE_ERROR_LOG, "Set Tx Switch failed\n");
            osMutexRelease(swMutex);
            continue;
          }
          run_status.tx_switch_channel = 0;
          // Check
          if (Get_Current_Switch_Channel(TX_SWITCH_CHANNEL) != 0) {
            THROW_LOG(MSG_TYPE_ERROR_LOG, "Set Tx Switch failed 2\n");
            osMutexRelease(swMutex);
            continue;
          }
          Set_Switch_Ready(TX_SWITCH_CHANNEL);
        }

        Clear_Switch_Ready(RX_SWITCH_CHANNEL);
        if (Set_Switch(RX_SWITCH_CHANNEL, 0)) {
          run_status.rx_switch_channel = 0xFF;
          THROW_LOG(MSG_TYPE_ERROR_LOG, "Set Rx Switch failed\n");
          osMutexRelease(swMutex);
          continue;
        }
        run_status.rx_switch_channel = 0;
        // Check
        if (Get_Current_Switch_Channel(RX_SWITCH_CHANNEL) != 0) {
          THROW_LOG(MSG_TYPE_ERROR_LOG, "Set Rx Switch failed 2\n");
          osMutexRelease(swMutex);
          continue;
        }
        Set_Switch_Ready(RX_SWITCH_CHANNEL);
        osMutexRelease(swMutex);
      } else if (run_status.osc_status == OSC_FAILURE) {
        if ((status = osMutexAcquire(swMutex, 50)) != osOK) {
          THROW_LOG(MSG_TYPE_ERROR_LOG, "Acquire mutex of sw failed\n");
          continue;
        }

        Reset_Switch(TX_SWITCH_CHANNEL);

        Clear_Switch_Ready(RX_SWITCH_CHANNEL);
        if (Set_Switch(RX_SWITCH_CHANNEL, 0)) {
          run_status.rx_switch_channel = 0xFF;
          THROW_LOG(MSG_TYPE_ERROR_LOG, "Set Rx Switch failed\n");
          osMutexRelease(swMutex);
          continue;
        }
        run_status.rx_switch_channel = 0;
        // Check
        if (Get_Current_Switch_Channel(RX_SWITCH_CHANNEL) != 0) {
          THROW_LOG(MSG_TYPE_ERROR_LOG, "Set Rx Switch failed 2\n");
          osMutexRelease(swMutex);
          continue;
        }
        Set_Switch_Ready(RX_SWITCH_CHANNEL);
        osMutexRelease(swMutex);
      }
    }
  }
}

void swIsrTask(void *argument)
{
  osStatus_t status;
  MsgStruct msg;

  for (;;)
  {
    status = osMessageQueueGet(mid_SwISR, &msg, 0U, osWaitForever);
    if (status != osOK)
      continue;

    if (msg.type == MSG_TYPE_SWITCH_DAC_ISR) {
      if (sw_tim_control.cur_x < sw_tim_control.dst_x) {
        sw_tim_control.cur_x = (sw_tim_control.dst_x - sw_tim_control.cur_x > sw_tim_control.step) ?\
                                (sw_tim_control.cur_x + sw_tim_control.step) : (sw_tim_control.dst_x);
      } else if (sw_tim_control.cur_x > sw_tim_control.dst_x) {
        sw_tim_control.cur_x = (sw_tim_control.cur_x - sw_tim_control.dst_x > sw_tim_control.step) ?\
                                (sw_tim_control.cur_x - sw_tim_control.step) : (sw_tim_control.dst_x);
      }

      if (sw_tim_control.cur_y < sw_tim_control.dst_y) {
        sw_tim_control.cur_y = (sw_tim_control.dst_y - sw_tim_control.cur_y > sw_tim_control.step) ?\
                                (sw_tim_control.cur_y + sw_tim_control.step) : (sw_tim_control.dst_y);
      } else if (sw_tim_control.cur_y > sw_tim_control.dst_y) {
        sw_tim_control.cur_y = (sw_tim_control.cur_y - sw_tim_control.dst_y > sw_tim_control.step) ?\
                                (sw_tim_control.cur_y - sw_tim_control.step) : (sw_tim_control.dst_y);
      }

      set_sw_dac_2(sw_tim_control.sw_num, sw_tim_control.cur_x, sw_tim_control.cur_y);

      if (sw_tim_control.cur_x == sw_tim_control.dst_x && sw_tim_control.cur_y == sw_tim_control.dst_y) {
        osSemaphoreRelease(switchSemaphore);
      } else {
        HAL_TIM_Base_Start_IT(&htim6);
      }
    }
  }
}

void logTask(void *argument)
{
  MsgStruct log_msg;
  osStatus_t status;
  uint32_t write_length;
  uint8_t remainder;

  uint32_t error_overflow_addr;
  uint32_t error_next_sector_addr;
  uint8_t error_next_sector;

  uint32_t normal_overflow_addr;
  uint32_t normal_next_sector_addr;
  uint8_t normal_next_sector;

  osDelay(pdMS_TO_TICKS(500));

  if (log_file_state.error_cur_sector == ERROR_LOG_FIRST_SECTOR + error_file_flash_count - 1) {
    error_overflow_addr = error_file_flash_end + 1;
    error_next_sector_addr = error_file_flash_addr[0];
    error_next_sector = ERROR_LOG_FIRST_SECTOR;
  } else {
    error_next_sector_addr = error_overflow_addr = error_file_flash_addr[log_file_state.error_cur_sector - ERROR_LOG_FIRST_SECTOR + 1];
    error_next_sector = log_file_state.error_cur_sector + 1;
  }

  if (log_file_state.normal_cur_sector == NORMAL_LOG_FIRST_SECTOR + normal_file_flash_count - 1) {
    normal_overflow_addr = normal_file_flash_end + 1;
    normal_next_sector_addr = normal_file_flash_addr[0];
    normal_next_sector = NORMAL_LOG_FIRST_SECTOR;
  } else {
    normal_next_sector_addr = normal_overflow_addr = normal_file_flash_addr[log_file_state.normal_cur_sector - NORMAL_LOG_FIRST_SECTOR + 1];
    normal_next_sector = log_file_state.normal_cur_sector + 1;
  }

  for (;;)
  {
    status = osMessageQueueGet(mid_LogMsg, &log_msg, 0U, osWaitForever);
    if (status != osOK)
      continue;

    if (log_msg.type == MSG_TYPE_ERROR_LOG) {
      if (log_file_state.error_offset >= error_file_flash_end + 1 || log_file_state.error_offset < error_file_flash_addr[0]) {
        Set_Flag(&run_status.internal_exp, INT_EXP_LOG_TASK);
        continue;
      }

      // The final amount of data written to flash must be an integer multiple of 4
      remainder = log_msg.length % 4;
      if (remainder) remainder = 4 - remainder;
      if (log_file_state.error_offset + log_msg.length + remainder >= error_overflow_addr) {
        // 1. fill the rest space with ' '
        Log_Write_byte(log_file_state.error_offset, ' ', error_overflow_addr - log_file_state.error_offset - 4);
        Log_Write_byte(log_file_state.error_offset + error_overflow_addr - log_file_state.error_offset - 4, '\n', 4);

        // 2. erase flash
        while (flash_in_use) {
          osDelay(pdMS_TO_TICKS(200));
        }
        //THROW_LOG("Log space overflow, erasing flash sector %u\n", next_sector);
        osSemaphoreAcquire(logEraseSemaphore, 0);
        if (FLASH_If_Erase_IT(error_next_sector) == FLASHIF_OK) {
          flash_in_use = 1;
        } else {
          Set_Flag(&run_status.internal_exp, INT_EXP_LOG_ERASE);
        }

        // 3. waiting for completion
        osSemaphoreAcquire(logEraseSemaphore, osWaitForever);

        // 4. update log_file_state, overflow_addr and next_***s
        log_file_state.error_offset = error_next_sector_addr;
        log_file_state.error_cur_sector = error_next_sector;
        if (log_file_state.error_cur_sector == ERROR_LOG_FIRST_SECTOR + error_file_flash_count - 1) {
          error_overflow_addr = error_file_flash_end + 1;
          error_next_sector_addr = error_file_flash_addr[0];
          error_next_sector = ERROR_LOG_FIRST_SECTOR;
        } else {
          error_next_sector_addr = error_overflow_addr = error_file_flash_addr[log_file_state.error_cur_sector - ERROR_LOG_FIRST_SECTOR + 1];
          error_next_sector = log_file_state.error_cur_sector + 1;
        }
        if (log_file_state.error_offset == log_file_state.error_header) {
          log_file_state.error_header = error_next_sector_addr;
        }
      }

      EPT("Writing log to flash address %#X, header = %#X\n", log_file_state.offset, log_file_state.header);
      while (flash_in_use) {
        EPT("Flash in using...\n");
        osDelay(pdMS_TO_TICKS(200));
      }
      write_length = Log_Write(log_file_state.error_offset, log_msg.pbuf, log_msg.length);
      log_file_state.error_offset += write_length;
    } else if (log_msg.type == MSG_TYPE_NORMAL_LOG) {
      if (log_file_state.normal_offset >= normal_file_flash_end + 1 || log_file_state.normal_offset < normal_file_flash_addr[0]) {
        Set_Flag(&run_status.internal_exp, INT_EXP_LOG_TASK);
        continue;
      }

      // The final amount of data written to flash must be an integer multiple of 4
      remainder = log_msg.length % 4;
      if (remainder) remainder = 4 - remainder;
      if (log_file_state.normal_offset + log_msg.length + remainder >= normal_overflow_addr) {
        // 1. fill the rest space with ' '
        Log_Write_byte(log_file_state.normal_offset, ' ', normal_overflow_addr - log_file_state.normal_offset - 4);
        Log_Write_byte(log_file_state.normal_offset + normal_overflow_addr - log_file_state.normal_offset - 4, '\n', 4);

        // 2. erase flash
        while (flash_in_use) {
          osDelay(pdMS_TO_TICKS(200));
        }
        //THROW_LOG("Log space overflow, erasing flash sector %u\n", next_sector);
        osSemaphoreAcquire(logEraseSemaphore, 0);
        if (FLASH_If_Erase_IT(normal_next_sector) == FLASHIF_OK) {
          flash_in_use = 1;
        } else {
          Set_Flag(&run_status.internal_exp, INT_EXP_LOG_ERASE);
        }

        // 3. waiting for completion
        osSemaphoreAcquire(logEraseSemaphore, osWaitForever);

        // 4. update log_file_state, overflow_addr and next_***s
        log_file_state.normal_offset = normal_next_sector_addr;
        log_file_state.normal_cur_sector = normal_next_sector;
        if (log_file_state.normal_cur_sector == NORMAL_LOG_FIRST_SECTOR + normal_file_flash_count - 1) {
          normal_overflow_addr = normal_file_flash_end + 1;
          normal_next_sector_addr = normal_file_flash_addr[0];
          normal_next_sector = NORMAL_LOG_FIRST_SECTOR;
        } else {
          normal_next_sector_addr = normal_overflow_addr = normal_file_flash_addr[log_file_state.normal_cur_sector - NORMAL_LOG_FIRST_SECTOR + 1];
          normal_next_sector = log_file_state.normal_cur_sector + 1;
        }
        if (log_file_state.normal_offset == log_file_state.normal_header) {
          log_file_state.normal_header = normal_next_sector_addr;
        }
      }

      EPT("Writing log to flash address %#X, header = %#X\n", log_file_state.offset, log_file_state.header);
      while (flash_in_use) {
        EPT("Flash in using...\n");
        osDelay(pdMS_TO_TICKS(200));
      }
      write_length = Log_Write(log_file_state.normal_offset, log_msg.pbuf, log_msg.length);
      log_file_state.normal_offset += write_length;
    } else {
      Set_Flag(&run_status.internal_exp, INT_EXP_LOG_TASK);
      continue;
    }

    vPortFree(log_msg.pbuf);

    if (osMessageQueueGetCount(mid_LogMsg) == 0) {
      // update log_file_state to eeprom/flash
      Update_Log_Status(&log_file_state);
    }
  }
}

void monitorTask(void *argument)
{
  osStatus_t status;
  uint16_t value;
  uint8_t ret;
  double voltage, temp;
  MsgStruct msg;

  osDelay(pdMS_TO_TICKS(500));

  if (!(IS_RESETFLAG_SET(SFT_RESET_BIT) || IS_RESETFLAG_SET(IWDG_RESET_BIT))) {
    if (Set_Switch(RX_SWITCH_CHANNEL, 0)) {
      run_status.rx_switch_channel = 0xFF;
    }
    run_status.rx_switch_channel = 0;
    // Check
    if (Get_Current_Switch_Channel(RX_SWITCH_CHANNEL) != 0) {
      Reset_Switch(RX_SWITCH_CHANNEL);
    } else {
      Set_Switch_Ready(RX_SWITCH_CHANNEL);
    }
  }

  device_busy = 0;

  for (;;) {
    // 2x32 Switch Block signal
    if (HAL_GPIO_ReadPin(SW1_BLOCK_GPIO_Port, SW1_BLOCK_Pin) == GPIO_PIN_RESET) {
      if (!run_status.tx_block) {
        Clear_Switch_Ready(TX_SWITCH_CHANNEL);
        Reset_Switch_Only(TX_SWITCH_CHANNEL);
        run_status.tx_block = 1;
      }
    } else {
      if (run_status.tx_block) {
        if (run_status.tx_switch_channel != 0xFF) {
          if (Set_Switch(TX_SWITCH_CHANNEL, run_status.tx_switch_channel)) {
            THROW_LOG(MSG_TYPE_ERROR_LOG, "Set Tx Switch failed\n");
            run_status.tx_switch_channel = 0xFF;
            continue;
          }

          // Check
          if (Get_Current_Switch_Channel(TX_SWITCH_CHANNEL) != run_status.tx_switch_channel) {
            THROW_LOG(MSG_TYPE_NORMAL_LOG, "Check Switch abnormal\n");
            Reset_Switch(TX_SWITCH_CHANNEL);
            continue;
          } else {
            Set_Switch_Ready(TX_SWITCH_CHANNEL);
          }
        }
        run_status.tx_block = 0;
      }
    }

    // PRO_Dis signal
    if (HAL_GPIO_ReadPin(PRO_DIS_N_GPIO_Port, PRO_DIS_N_Pin) == GPIO_PIN_RESET) {
      if (!run_status.tosa_enable && allow_tosa && !enable_tosa_failed) {
        run_status.tosa_enable = 1;
        msg.type = MSG_TYPE_LAZER_ENABLE;
        osMessageQueuePut(mid_LazerManager, &msg, 0U, 0U);
      }
    } else {
      enable_tosa_failed = 0;
      if (run_status.tosa_enable) {
        run_status.tosa_enable = 0;
        msg.type = MSG_TYPE_LAZER_DISABLE;
        osMessageQueuePut(mid_LazerManager, &msg, 0U, 0U);
      }
    }

    // Alarm
    status = RTOS_ADC7828_Read(VOLTAGE_3_3_CHANNEL, &value);
    if (status != osOK) {
      Set_Flag(&run_status.internal_exp, INT_EXP_OS_ERR);
    } else {
      voltage = (double)value / 4096 * 2.5 * 2;
      if (!Is_Flag_Set(&run_status.exp, EXP_VOLTAGE_3_3)) {
        if (voltage > run_status.thr_table.vol_3_3_high_alarm || voltage < run_status.thr_table.vol_3_3_low_alarm) {
          THROW_LOG(MSG_TYPE_NORMAL_LOG, "Voltage 3.3V abnormal, current voltage = %.3lfV\n", voltage);
          Set_Flag(&run_status.exp, EXP_VOLTAGE_3_3);
        }
      } else {
        if (voltage <= run_status.thr_table.vol_3_3_high_clear && voltage >= run_status.thr_table.vol_3_3_low_clear) {
          THROW_LOG(MSG_TYPE_NORMAL_LOG, "Voltage 3.3V back to normal\n");
          Clear_Flag(&run_status.exp, EXP_VOLTAGE_3_3);
        }
      }
    }

    status = RTOS_ADC7953_SPI5_Read(TEC_ADC_VOLTAGE_4_4_CHANNEL, &value);
    if (status != osOK) {
      Set_Flag(&run_status.internal_exp, INT_EXP_OS_ERR);
    } else {
      voltage = (double)value / 4096 * 2.5 * 3;
      if (!Is_Flag_Set(&run_status.exp, EXP_VOLTAGE_4_4)) {
        if (voltage > run_status.thr_table.vol_4_4_high_alarm || voltage < run_status.thr_table.vol_4_4_low_alarm) {
          THROW_LOG(MSG_TYPE_NORMAL_LOG, "Voltage 4.4V abnormal, current voltage = %.3lfV\n", voltage);
          Set_Flag(&run_status.exp, EXP_VOLTAGE_4_4);
        }
      } else {
        if (voltage <= run_status.thr_table.vol_4_4_high_clear && voltage >= run_status.thr_table.vol_4_4_low_clear) {
          THROW_LOG(MSG_TYPE_NORMAL_LOG, "Voltage 4.4V back to normal\n");
          Clear_Flag(&run_status.exp, EXP_VOLTAGE_4_4);
        }
      }
    }

    status = RTOS_ADC7828_Read(VOLTAGE_5_0_CHANNEL, &value);
    if (status != osOK) {
      Set_Flag(&run_status.internal_exp, INT_EXP_OS_ERR);
      value = 0;
    } else {
      voltage = (double)value / 4096 * 2.5 * 3;
      if (!Is_Flag_Set(&run_status.exp, EXP_VOLTAGE_5_0)) {
        if (voltage > run_status.thr_table.vol_5_0_high_alarm || voltage < run_status.thr_table.vol_5_0_low_alarm) {
          THROW_LOG(MSG_TYPE_NORMAL_LOG, "Voltage 5V abnormal, current voltage = %.3lfV\n", voltage);
          Set_Flag(&run_status.exp, EXP_VOLTAGE_5_0);
        }
      } else {
        if (voltage <= run_status.thr_table.vol_5_0_high_clear && voltage >= run_status.thr_table.vol_5_0_low_clear) {
          THROW_LOG(MSG_TYPE_NORMAL_LOG, "Voltage 5V back to normal\n");
          Clear_Flag(&run_status.exp, EXP_VOLTAGE_5_0);
        }
      }
    }

    status = RTOS_ADC7828_Read(VOLTAGE_61_0_CHANNEL, &value);
    if (status != osOK) {
      Set_Flag(&run_status.internal_exp, INT_EXP_OS_ERR);
      value = 0;
    } else {
      voltage = (double)value / 4096 * 2.5 * 51;
      if (!Is_Flag_Set(&run_status.exp, EXP_VOLTAGE_61_0)) {
        if (voltage > run_status.thr_table.vol_61_0_high_alarm || voltage < run_status.thr_table.vol_61_0_low_alarm) {
          THROW_LOG(MSG_TYPE_NORMAL_LOG, "Voltage 64V abnormal, current voltage = %.3lfV\n", voltage);
          Set_Flag(&run_status.exp, EXP_VOLTAGE_61_0);
        }
      } else {
        if (voltage <= run_status.thr_table.vol_61_0_high_clear && voltage >= run_status.thr_table.vol_61_0_low_clear) {
          THROW_LOG(MSG_TYPE_NORMAL_LOG, "Voltage 64V back to normal\n");
          Clear_Flag(&run_status.exp, EXP_VOLTAGE_61_0);
        }
      }
    }

    status = RTOS_ADC7828_Read(TEMPERATURE_CHANNEL, &value);
    if (status != osOK) {
      Set_Flag(&run_status.internal_exp, INT_EXP_OS_ERR);
      value = 0;
    } else {
      temp = Cal_Temp(value);
      if (!Is_Flag_Set(&run_status.exp, EXP_TEMPERATURE)) {
        if (temp > run_status.thr_table.temp_high_alarm || temp < run_status.thr_table.temp_low_alarm) {
          THROW_LOG(MSG_TYPE_NORMAL_LOG, "Temperature abnormal, current temperature = %.3lfC\n", temp);
          Set_Flag(&run_status.exp, EXP_TEMPERATURE);
        }
      } else {
        if (temp <= run_status.thr_table.temp_high_clear && temp >= run_status.thr_table.temp_low_clear) {
          THROW_LOG(MSG_TYPE_NORMAL_LOG, "Temperature back to normal\n");
          Clear_Flag(&run_status.exp, EXP_TEMPERATURE);
        }
      }
    }

#if 1
    if (run_status.allow_monitor) {
      if (run_status.tosa_enable) {
        status = RTOS_ADC7953_SPI5_Read(TEC_ADC_TEC_CURRENT_CHANNEL, &value);
        if (status != osOK) {
          Set_Flag(&run_status.internal_exp, INT_EXP_OS_ERR);
        } else {
          voltage = (double)value / 4096 * 2.5;
          voltage = (voltage - 1.25) / 0.285 * 1000;
          if (!Is_Flag_Set(&run_status.exp, EXP_TEC_CURRENT)) {
            if (voltage > run_status.thr_table.tec_cur_high_alarm || voltage < run_status.thr_table.tec_cur_low_alarm) {
              THROW_LOG(MSG_TYPE_NORMAL_LOG, "Tec current abnormal, current current = %.lfmA\n", voltage);
              Set_Flag(&run_status.exp, EXP_TEC_CURRENT);
            }
          } else {
            if (voltage <= run_status.thr_table.tec_cur_high_clear && voltage >= run_status.thr_table.tec_cur_low_clear) {
              THROW_LOG(MSG_TYPE_NORMAL_LOG, "Tec current back to normal\n");
              Clear_Flag(&run_status.exp, EXP_TEC_CURRENT);
            }
          }
        }

        status = RTOS_ADC7953_SPI5_Read(TEC_ADC_TEC_VOLTAGE_CHANNEL, &value);
        if (status != osOK) {
          Set_Flag(&run_status.internal_exp, INT_EXP_OS_ERR);
        } else {
          voltage = (double)value / 4096 * 2.5;
          voltage = (voltage - 1.25) / 0.25 * 1000;
          if (!Is_Flag_Set(&run_status.exp, EXP_TEC_VOLTAGE)) {
            if (voltage > run_status.thr_table.tec_vol_high_alarm || voltage < run_status.thr_table.tec_vol_low_alarm) {
              THROW_LOG(MSG_TYPE_NORMAL_LOG, "Tec voltage abnormal, current voltage = %.lfmV\n", voltage);
              Set_Flag(&run_status.exp, EXP_TEC_VOLTAGE);
            }
          } else {
            if (voltage <= run_status.thr_table.tec_vol_high_clear && voltage >= run_status.thr_table.tec_vol_low_clear) {
              THROW_LOG(MSG_TYPE_NORMAL_LOG, "Tec voltage back to normal\n");
              Clear_Flag(&run_status.exp, EXP_TEC_VOLTAGE);
            }
          }
        }
      }
  #endif

      if (run_status.tosa_enable) {
        // Power
        if (!run_status.modulation) {
          if ((ret = get_tap_pd_power(&value, &voltage)) != 0) {
            if (!Is_Flag_Set(&run_status.internal_exp, INT_EXP_TAP_PD)) {
              THROW_LOG(MSG_TYPE_ERROR_LOG, "Get_Tap_Power error code = %u\n", ret);
              Set_Flag(&run_status.internal_exp, INT_EXP_TAP_PD);
            }
          } else {
            temp = run_status.tosa_dst_power_high - voltage;
            if (temp > 2 || temp < -2) {
              if (!Is_Flag_Set(&run_status.exp, EXP_LAZER_POWER)) {
                THROW_LOG(MSG_TYPE_NORMAL_LOG, "Tap power = %lf, destination is %lf\n", voltage, run_status.tosa_dst_power_high);
                Set_Flag(&run_status.exp, EXP_LAZER_POWER);
              }
            } else {
              if (Is_Flag_Set(&run_status.exp, EXP_LAZER_POWER)) {
                THROW_LOG(MSG_TYPE_NORMAL_LOG, "Tap power = %lf back to normal\n", voltage);
                Clear_Flag(&run_status.exp, EXP_LAZER_POWER);
              }
            }
          }
        }

        // TEC LOSS LOCK
        if (HAL_GPIO_ReadPin(TMPGD_GPIO_Port, TMPGD_Pin) == GPIO_PIN_RESET) {
          if (!Is_Flag_Set(&run_status.exp, EXP_TEC_TEMP_LOSS)) {
            THROW_LOG(MSG_TYPE_NORMAL_LOG, "TEC lock loss\n");
            Set_Flag(&run_status.exp, EXP_TEC_TEMP_LOSS);
          }
        } else {
          if (Is_Flag_Set(&run_status.exp, EXP_TEC_TEMP_LOSS)) {
            THROW_LOG(MSG_TYPE_NORMAL_LOG, "TEC locked\n");
            Clear_Flag(&run_status.exp, EXP_TEC_TEMP_LOSS);
          }
        }

        // Tec Temperature
        status = RTOS_ADC7953_SPI5_Read(TEC_ADC_TEC_TEMP_CHANNEL, &value);
        if (status != osOK) {
          Set_Flag(&run_status.internal_exp, INT_EXP_OS_ERR);
          value = 0;
        } else {
          temp = Cal_Tosa_Temp(value);
          if (!Is_Flag_Set(&run_status.exp, EXP_TEC_TEMP)) {
            if (temp > run_status.thr_table.tec_temp_high_alarm || temp < run_status.thr_table.tec_temp_low_alarm) {
              THROW_LOG(MSG_TYPE_NORMAL_LOG, "Tec Temperature abnormal, current temperature = %.3lfC\n", temp);
              Set_Flag(&run_status.exp, EXP_TEC_TEMP);
            }
          } else {
            if (temp <= run_status.thr_table.tec_temp_high_clear && temp >= run_status.thr_table.tec_temp_low_clear) {
              THROW_LOG(MSG_TYPE_NORMAL_LOG, "Tec Temperature back to normal\n");
              Clear_Flag(&run_status.exp, EXP_TEC_TEMP);
            }
          }
        }

        // LD Current
        status = RTOS_ADC7953_SPI5_Read(TEC_ADC_LD_CURRENT_CHANNEL, &value);
        if (status != osOK) {
          Set_Flag(&run_status.internal_exp, INT_EXP_OS_ERR);
          value = 0;
        } else {
          temp = (double)value / 4096 * 2.5;
          temp = temp / 22 * 1000;
          if (!Is_Flag_Set(&run_status.exp, EXP_LAZER_CURRENT)) {
            if (temp > run_status.thr_table.LD_cur_high_alarm) {
              THROW_LOG(MSG_TYPE_NORMAL_LOG, "LD Current abnormal, current temperature = %.3lfC\n", temp);
              Set_Flag(&run_status.exp, EXP_LAZER_CURRENT);
            }
          } else {
            if (temp <= run_status.thr_table.LD_cur_high_clear) {
              THROW_LOG(MSG_TYPE_NORMAL_LOG, "LD Current back to normal\n");
              Clear_Flag(&run_status.exp, EXP_LAZER_CURRENT);
            }
          }
        }
      }
    }

    if (run_status.exp && !run_status.pre_alarm) {
      Set_Alarm();
      if (Update_History_Alarm(run_status.exp) != osOK) {
        Set_Flag(&run_status.internal_exp, INT_EXP_UP_ALARM);
      }
      run_status.pre_alarm = 1;
      run_status.pre_exp_value = run_status.exp;
    } else if (!run_status.exp && run_status.pre_alarm) {
      Clear_Alarm();
      run_status.pre_alarm = 0;
      run_status.pre_exp_value = 0;
    } else if (run_status.exp && run_status.pre_alarm) {
      if (run_status.exp != run_status.pre_exp_value) {
        if (Update_History_Alarm(run_status.exp) != osOK) {
          Set_Flag(&run_status.internal_exp, INT_EXP_UP_ALARM);
        }
        run_status.pre_exp_value = run_status.exp;
      }
    }

    if (run_status.modulation) {
      osDelay(pdMS_TO_TICKS(1000));
    } else {
      osDelay(pdMS_TO_TICKS(300));
    }
  }
}

void lazerManagerTask(void *argument)
{
  osStatus_t status;
  uint8_t buf[2];
  uint8_t ret;
  MsgStruct msg;
  double power_cur, power_sub, power_dst;
  uint32_t i, times;

  osDelay(pdMS_TO_TICKS(500));

  for (;;)
  {
    status = osMessageQueueGet(mid_LazerManager, &msg, 0U, osWaitForever);
    if (status != osOK)
      continue;

    if (msg.type == MSG_TYPE_LAZER_ENABLE) {
      run_status.tosa_high = Get_Tosa_Data(run_status.tosa_dst_power_high);
      run_status.tosa_low = Get_Tosa_Data(run_status.tosa_dst_power_low);

      if (run_status.modulation) {
        status = RTOS_DAC128S085_Write(DAC128S085_TEC_VALUE_CHANNEL, (run_status.tosa_high.tec_dac + run_status.tosa_low.tec_dac) / 2, DAC128S085_MODE_NORMAL);
        if (run_status.power_mode) {
          RTOS_DAC128S085_Write(DAC128S085_TOSA_POWER_CHANNEL, run_status.tosa_high.tosa_dac, DAC128S085_MODE_NORMAL);
        } else {
          RTOS_DAC128S085_Write(DAC128S085_TOSA_POWER_CHANNEL, run_status.tosa_low.tosa_dac, DAC128S085_MODE_NORMAL);
        }
      } else {
        status = RTOS_DAC128S085_Write(DAC128S085_TEC_VALUE_CHANNEL, run_status.tosa_high.tec_dac, DAC128S085_MODE_NORMAL);
        RTOS_DAC128S085_Write(DAC128S085_TOSA_POWER_CHANNEL, run_status.tosa_high.tosa_dac, DAC128S085_MODE_NORMAL);
      }

      if ((ret = Enable_Tosa()) != 0) {
        Set_Flag(&run_status.internal_exp, INT_EXP_TOSA);
        THROW_LOG(MSG_TYPE_ERROR_LOG, "Enable Tosa failed, ret = %u\n", ret);
        enable_tosa_failed = 1;
        continue;
      }
      osDelay(pdMS_TO_TICKS(100));

      if (!run_status.modulation) {
        if (Cali_Power(run_status.tosa_dst_power_high)) {
          allow_tosa = 0;
          run_status.tosa_enable = 0;
          THROW_LOG(MSG_TYPE_NORMAL_LOG, "Module has disabled Tosa until reset\n");
          Disable_Tosa();
          continue;
        }
      }

      Set_Lazer_Ready();

      i = 0;
      times = 0;
      while (i++ < 100) {
        if (Is_Tec_Lock()) {
          if (++times > 5) {
            break;
          }
        }
        osDelay(5);
      }
      if (times > 5) {
        Update_Tec_Dest_Temp(&run_status.thr_table);
      } else {
        THROW_LOG(MSG_TYPE_ERROR_LOG, "TMPGD error\n");
        Set_Flag(&run_status.exp, EXP_TEC_TEMP_LOSS);
        break;
      }
      run_status.allow_monitor = 1;
    } else if (msg.type == MSG_TYPE_LAZER_DISABLE) {
      run_status.allow_monitor = 0;
      Clear_Lazer_Ready();

      Disable_Tosa();
    } else if (msg.type == MSG_TYPE_LAZER_POWER) {
      //msg.type = MSG_TYPE_CMD_PROCESS;
      //msg.pbuf = pvPortMalloc(1);
      //msg.length = 1;

      run_status.tosa_high = Get_Tosa_Data(run_status.tosa_dst_power_high);
      run_status.tosa_low = Get_Tosa_Data(run_status.tosa_dst_power_low);

      if (run_status.tosa_enable) {
        run_status.allow_monitor = 0;

        if (run_status.modulation) {
          status = RTOS_DAC128S085_Write(DAC128S085_TEC_VALUE_CHANNEL, (run_status.tosa_high.tec_dac + run_status.tosa_low.tec_dac) / 2, DAC128S085_MODE_NORMAL);
          if (run_status.power_mode) {
            RTOS_DAC128S085_Write(DAC128S085_TOSA_POWER_CHANNEL, run_status.tosa_high.tosa_dac, DAC128S085_MODE_NORMAL);
          } else {
            RTOS_DAC128S085_Write(DAC128S085_TOSA_POWER_CHANNEL, run_status.tosa_low.tosa_dac, DAC128S085_MODE_NORMAL);
          }
        } else {
          status = RTOS_DAC128S085_Write(DAC128S085_TEC_VALUE_CHANNEL, run_status.tosa_high.tec_dac, DAC128S085_MODE_NORMAL);
          RTOS_DAC128S085_Write(DAC128S085_TOSA_POWER_CHANNEL, run_status.tosa_high.tosa_dac, DAC128S085_MODE_NORMAL);
          osDelay(1);
          if (Cali_Power(run_status.tosa_dst_power_high)) {
            THROW_LOG(MSG_TYPE_NORMAL_LOG, "Module has disabled Tosa until reset\n");
            allow_tosa = 0;
            run_status.tosa_enable = 0;
            Disable_Tosa();
            // return failure
            //*(uint8_t*)msg.pbuf = 1;
            //osMessageQueuePut(mid_CmdProcess, &msg, 0U, 0U);
            continue;
          }
        }

        // return success
        //*(uint8_t*)msg.pbuf = 0;
        //osMessageQueuePut(mid_CmdProcess, &msg, 0U, 0U);

        i = 0;
        times = 0;
        while (i++ < 100) {
          if (Is_Tec_Lock()) {
            if (++times > 5) {
              break;
            }
          }
          osDelay(5);
        }
        if (times > 5) {
          Update_Tec_Dest_Temp(&run_status.thr_table);
        } else {
          THROW_LOG(MSG_TYPE_ERROR_LOG, "TMPGD error\n");
          Set_Flag(&run_status.exp, EXP_TEC_TEMP_LOSS);
          break;
        }
        run_status.allow_monitor = 1;
      } else {
        // return success
        //*(uint8_t*)msg.pbuf = 0;
        //osMessageQueuePut(mid_CmdProcess, &msg, 0U, 0U);
      }
    } else if (msg.type == MSG_TYPE_MODULATION_ON) {
      //msg.type = MSG_TYPE_CMD_PROCESS;
      //msg.pbuf = pvPortMalloc(1);
      //msg.length = 1;

      if (run_status.tosa_enable) {
        run_status.allow_monitor = 0;

        status = RTOS_DAC128S085_Write(DAC128S085_TEC_VALUE_CHANNEL, (run_status.tosa_high.tec_dac + run_status.tosa_low.tec_dac) / 2, DAC128S085_MODE_NORMAL);

        run_status.modulation = 1;
        HAL_TIM_IC_Start_IT(&htim8, TIM_CHANNEL_1);
        HAL_TIM_IC_Start_IT(&htim8, TIM_CHANNEL_3);

        i = 0;
        times = 0;
        while (i++ < 100) {
          if (Is_Tec_Lock()) {
            if (++times > 5) {
              break;
            }
          }
          osDelay(5);
        }
        if (times > 5) {
          Update_Tec_Dest_Temp(&run_status.thr_table);
        } else {
          THROW_LOG(MSG_TYPE_ERROR_LOG, "TMPGD error\n");
          Set_Flag(&run_status.exp, EXP_TEC_TEMP_LOSS);
          break;
        }
        run_status.allow_monitor = 1;
      } else {
        run_status.modulation = 1;
        HAL_TIM_IC_Start_IT(&htim8, TIM_CHANNEL_1);
        HAL_TIM_IC_Start_IT(&htim8, TIM_CHANNEL_3);
      }

      //*(uint8_t*)msg.pbuf = 0;
      //osMessageQueuePut(mid_CmdProcess, &msg, 0U, 0U);

    } else if (msg.type == MSG_TYPE_MODULATION_OFF) {
      //msg.type = MSG_TYPE_CMD_PROCESS;
      //msg.pbuf = pvPortMalloc(1);
      //msg.length = 1;

      HAL_TIM_IC_Stop_IT(&htim8, TIM_CHANNEL_1);
      HAL_TIM_IC_Stop_IT(&htim8, TIM_CHANNEL_3);

      run_status.power_mode = 1;

      if (run_status.tosa_enable) {
        run_status.allow_monitor = 0;

        status = RTOS_DAC128S085_Write(DAC128S085_TEC_VALUE_CHANNEL, run_status.tosa_high.tec_dac, DAC128S085_MODE_NORMAL);
        RTOS_DAC128S085_Write(DAC128S085_TOSA_POWER_CHANNEL, run_status.tosa_high.tosa_dac, DAC128S085_MODE_NORMAL);
        osDelay(pdMS_TO_TICKS(1));

        if (Cali_Power(run_status.tosa_dst_power_high)) {
          THROW_LOG(MSG_TYPE_NORMAL_LOG, "Module has disabled Tosa until reset\n");
          allow_tosa = 0;
          run_status.tosa_enable = 0;
          Disable_Tosa();
          // return failure
          //*(uint8_t*)msg.pbuf = 1;
          //osMessageQueuePut(mid_CmdProcess, &msg, 0U, 0U);
          continue;
        }

        i = 0;
        times = 0;
        while (i++ < 100) {
          if (Is_Tec_Lock()) {
            if (++times > 5) {
              break;
            }
          }
          osDelay(5);
        }
        if (times > 5) {
          Update_Tec_Dest_Temp(&run_status.thr_table);
        } else {
          THROW_LOG(MSG_TYPE_ERROR_LOG, "TMPGD error\n");
          Set_Flag(&run_status.exp, EXP_TEC_TEMP_LOSS);
          break;
        }
        run_status.allow_monitor = 1;
      }

      run_status.modulation = 0;
      //*(uint8_t*)msg.pbuf = 0;
      //osMessageQueuePut(mid_CmdProcess, &msg, 0U, 0U);
    } else if (msg.type == MSG_TYPE_SELF_TEST) {
      if (Is_Flag_Set(&run_status.exp, EXP_SELFCHECK)) {
        Clear_Flag(&run_status.exp, EXP_SELFCHECK);
      }
      if (Is_Flag_Set(&run_status.exp, EXP_RX_PD)) {
        Clear_Flag(&run_status.exp, EXP_RX_PD);
      }
      if (Is_Flag_Set(&run_status.exp, EXP_SWITCH)) {
        Clear_Flag(&run_status.exp, EXP_SWITCH);
      }

      run_status.osc_status = OSC_ONGOING;
      msg.type = MSG_TYPE_SELF_CHECK_SWITCH;
      msg.pbuf = NULL;
      osMessageQueuePut(mid_ISR, &msg, 0U, 0U);
    } else if (msg.type == MSG_TYPE_SELF_TEST_STEP_2) {
      msg.type = MSG_TYPE_SELF_CHECK_SWITCH;
      msg.pbuf = NULL;
      if (run_status.osc_status == OSC_FAILURE) {
        if (!Is_Flag_Set(&run_status.exp, EXP_SELFCHECK)) {
          Set_Flag(&run_status.exp, EXP_SELFCHECK);
        }
        osMessageQueuePut(mid_ISR, &msg, 0U, 0U);
        continue;
      }

      if ((ret = Get_Tap_Power(&power_cur)) != 0) {
        THROW_LOG(MSG_TYPE_NORMAL_LOG, "Self-check failed because get tap-pd failed.\n");
        THROW_LOG(MSG_TYPE_ERROR_LOG, "Get_Tap_Power error code = %u when self_check\n", ret);
        Set_Flag(&run_status.internal_exp, INT_EXP_TAP_PD);
        if (!Is_Flag_Set(&run_status.exp, EXP_SELFCHECK)) {
          Set_Flag(&run_status.exp, EXP_SELFCHECK);
        }
        run_status.osc_status = OSC_FAILURE;
        osMessageQueuePut(mid_ISR, &msg, 0U, 0U);
        continue;
      }
      power_sub = run_status.tosa_dst_power_high - power_cur;
      // THROW_LOG(MSG_TYPE_NORMAL_LOG, "Self-check Tap power = %lf, dest power is %lf\r\n", power_h, run_status.tosa_dst_power_high);
      if (power_sub > 2 || power_sub < -2) {
        THROW_LOG(MSG_TYPE_NORMAL_LOG, "Self-check failed.\n");
        THROW_LOG(MSG_TYPE_NORMAL_LOG, "Tap power = %lf, destination is %lf\n", power_cur, run_status.tosa_dst_power_high);
        if (!Is_Flag_Set(&run_status.exp, EXP_SELFCHECK)) {
          Set_Flag(&run_status.exp, EXP_SELFCHECK);
        }
        if (!Is_Flag_Set(&run_status.exp, EXP_LAZER_POWER)) {
          Set_Flag(&run_status.exp, EXP_LAZER_POWER);
        }
        run_status.osc_status = OSC_FAILURE;
        osMessageQueuePut(mid_ISR, &msg, 0U, 0U);
        continue;
      }

      if ((ret = Get_Rx_Power(&power_cur)) != 0) {
        THROW_LOG(MSG_TYPE_NORMAL_LOG, "Self-check failed because get rx-pd failed.\n");
        THROW_LOG(MSG_TYPE_ERROR_LOG, "Get_Rx_Power error code = %u when self_check\n", ret);
        Set_Flag(&run_status.internal_exp, INT_EXP_RX_PD);
        if (!Is_Flag_Set(&run_status.exp, EXP_SELFCHECK)) {
          Set_Flag(&run_status.exp, EXP_SELFCHECK);
        }
        run_status.osc_status = OSC_FAILURE;
        osMessageQueuePut(mid_ISR, &msg, 0U, 0U);
        continue;
      }
      status = RTOS_EEPROM_Read(EEPROM_ADDR, EE_CAL_LB_IL + 2, buf, 2);
      // power_dst is loopback insertion loss vale
      power_dst = (double)(int16_t)Buffer_To_BE16(buf) / 100;
      power_sub = run_status.tosa_dst_power_high - (power_cur + power_dst);
      // THROW_LOG(MSG_TYPE_NORMAL_LOG, "Self-check Rx power = %lf, IL = %lf, dest power is %lf, \r\n", power_h, power_dst, run_status.tosa_dst_power_high);
      if (power_sub > 3 || power_sub < -3) {
        THROW_LOG(MSG_TYPE_NORMAL_LOG, "Self-check failed.\n");
        THROW_LOG(MSG_TYPE_NORMAL_LOG, "Rx power = %lf, IL = %lf, destination is %lf\n", power_cur, power_dst, run_status.tosa_dst_power_high);
        if (power_sub > 60 || power_sub < -60) {
          if (!Is_Flag_Set(&run_status.exp, EXP_SWITCH)) {
            Set_Flag(&run_status.exp, EXP_SWITCH);
          }
        } else {
          if (!Is_Flag_Set(&run_status.exp, EXP_RX_PD)) {
            Set_Flag(&run_status.exp, EXP_RX_PD);
          }
        }
        if (!Is_Flag_Set(&run_status.exp, EXP_SELFCHECK)) {
          Set_Flag(&run_status.exp, EXP_SELFCHECK);
        }
        run_status.osc_status = OSC_FAILURE;
        osMessageQueuePut(mid_ISR, &msg, 0U, 0U);
        continue;
      }

      if (Is_Flag_Set(&run_status.exp, EXP_SELFCHECK)) {
        Clear_Flag(&run_status.exp, EXP_SELFCHECK);
      }
      run_status.osc_status = OSC_SUCCESS;
      osMessageQueuePut(mid_ISR, &msg, 0U, 0U);
    } else if (msg.type == MSG_TYPE_PRO_CTL_RAISING_ISR) {
      if (run_status.tosa_enable) {
        RTOS_DAC128S085_Write(DAC128S085_TOSA_POWER_CHANNEL, run_status.tosa_high.tosa_dac, DAC128S085_MODE_NORMAL);
      }
      run_status.power_mode = 1;
    } else if (msg.type == MSG_TYPE_PRO_CTL_FALLING_ISR) {
      if (run_status.tosa_enable) {
        RTOS_DAC128S085_Write(DAC128S085_TOSA_POWER_CHANNEL, run_status.tosa_low.tosa_dac, DAC128S085_MODE_NORMAL);
      }
      run_status.power_mode = 0;
    }
  }
}

/* USER CODE END Application */

/************************ (C) COPYRIGHT STMicroelectronics *****END OF FILE****/
